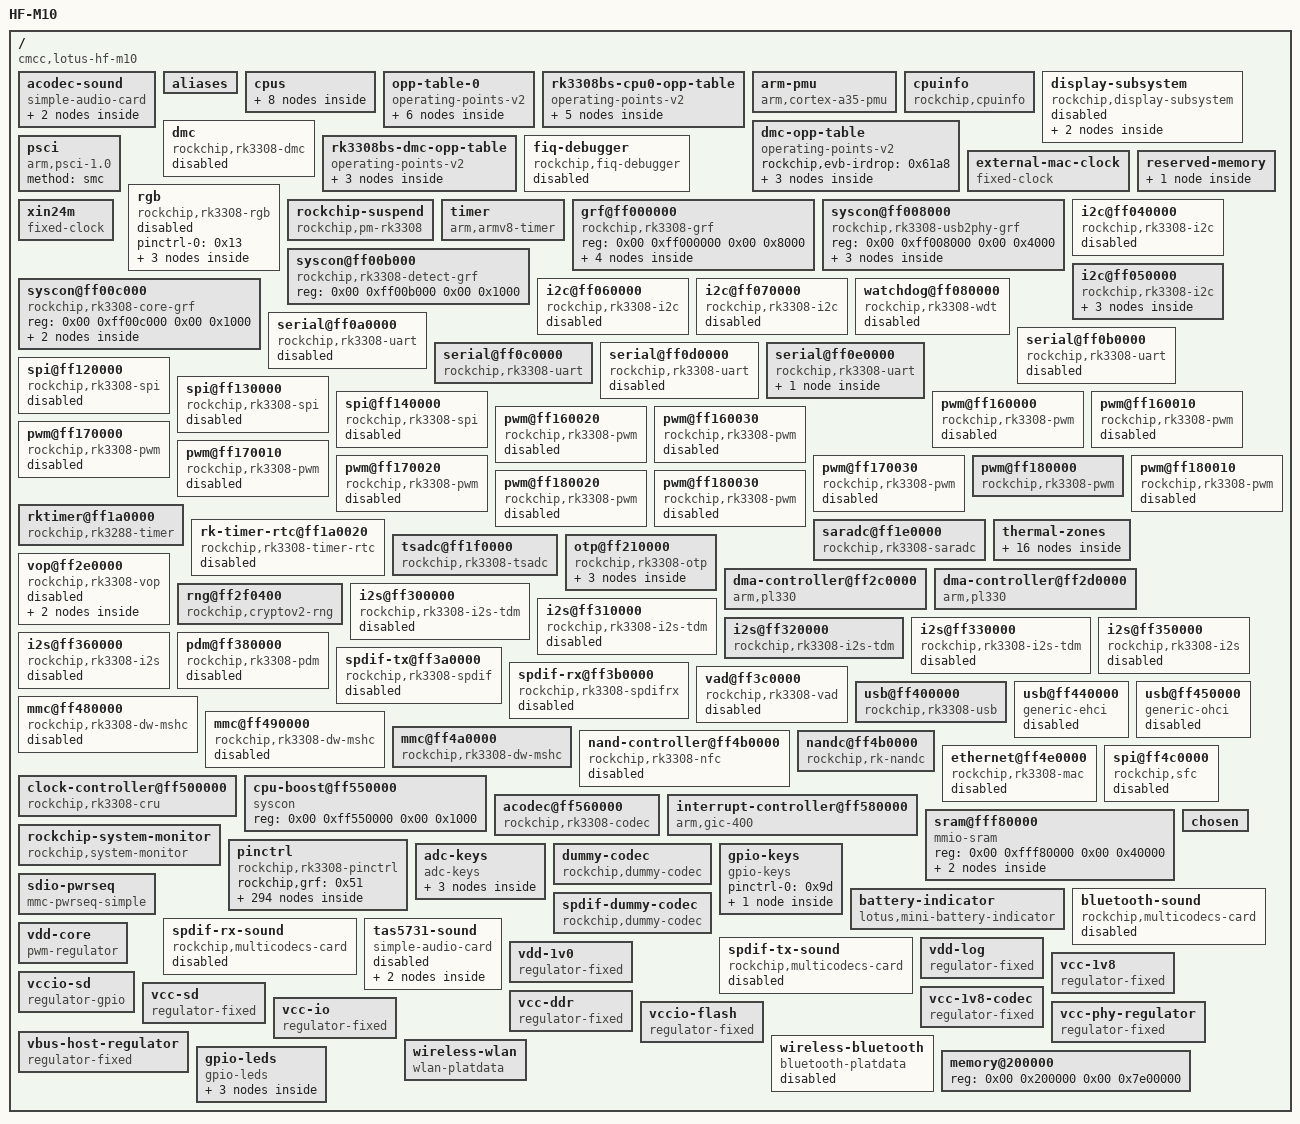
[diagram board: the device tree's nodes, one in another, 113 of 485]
/dts-v1/;

/ {
	compatible = "cmcc,lotus-hf-m10", "lotus,mini-rk3308", "rockchip,rk3308-evb-amic-v11", "rockchip,rk3308";
	interrupt-parent = <0x01>;
	#address-cells = <0x02>;
	#size-cells = <0x02>;
	model = "HF-M10";

	acodec-sound {
		simple-audio-card,mclk-fs = <0x100>;
		simple-audio-card,format = "i2s";
		simple-audio-card,name = "LotusMini";
		compatible = "simple-audio-card";

		simple-audio-card,codec {
			sound-dai = <0xa0>;
		};

		simple-audio-card,cpu {
			sound-dai = <0x9f>;
		};
	};

	aliases {
		ethernet0 = "/ethernet@ff4e0000";
		gpio0 = "/pinctrl/gpio@ff220000";
		gpio1 = "/pinctrl/gpio@ff230000";
		gpio2 = "/pinctrl/gpio@ff240000";
		gpio3 = "/pinctrl/gpio@ff250000";
		gpio4 = "/pinctrl/gpio@ff260000";
		i2c0 = "/i2c@ff040000";
		i2c1 = "/i2c@ff050000";
		i2c2 = "/i2c@ff060000";
		i2c3 = "/i2c@ff070000";
		serial0 = "/serial@ff0a0000";
		serial1 = "/serial@ff0b0000";
		serial2 = "/serial@ff0c0000";
		serial3 = "/serial@ff0d0000";
		serial4 = "/serial@ff0e0000";
		spi0 = "/spi@ff120000";
		spi1 = "/spi@ff130000";
		spi2 = "/spi@ff140000";
	};

	cpus {
		#address-cells = <0x02>;
		#size-cells = <0x00>;

		cpu@0 {
			device_type = "cpu";
			compatible = "arm,cortex-a35";
			reg = <0x00 0x00>;
			enable-method = "psci";
			clocks = <0x02 0x05>;
			#cooling-cells = <0x02>;
			dynamic-power-coefficient = <0x53>;
			operating-points-v2 = <0x03 0x04>;
			cpu-idle-states = <0x05>;
			next-level-cache = <0x06>;
			cpu-supply = <0x07>;
			phandle = <0x09>;

			power-model {
				compatible = "simple-power-model";
				leakage-range = <0x05 0x32>;
				ls = <0x17c6 0x18ca 0xffffffc1>;
				static-coefficient = <0x186a0>;
				ts = <0xfffe55b6 0x18c54 0xfffff9ac 0x1e>;
				thermal-zone = "soc-thermal";
			};
		};

		cpu@1 {
			device_type = "cpu";
			compatible = "arm,cortex-a35";
			reg = <0x00 0x01>;
			enable-method = "psci";
			operating-points-v2 = <0x03 0x04>;
			cpu-idle-states = <0x05>;
			next-level-cache = <0x06>;
			phandle = <0x0a>;
		};

		cpu@2 {
			device_type = "cpu";
			compatible = "arm,cortex-a35";
			reg = <0x00 0x02>;
			enable-method = "psci";
			operating-points-v2 = <0x03 0x04>;
			cpu-idle-states = <0x05>;
			next-level-cache = <0x06>;
			phandle = <0x0b>;
		};

		cpu@3 {
			device_type = "cpu";
			compatible = "arm,cortex-a35";
			reg = <0x00 0x03>;
			enable-method = "psci";
			operating-points-v2 = <0x03 0x04>;
			cpu-idle-states = <0x05>;
			next-level-cache = <0x06>;
			phandle = <0x0c>;
		};

		idle-states {
			entry-method = "psci";

			cpu-sleep {
				compatible = "arm,idle-state";
				local-timer-stop;
				arm,psci-suspend-param = <0x10000>;
				entry-latency-us = <0x78>;
				exit-latency-us = <0xfa>;
				min-residency-us = <0x384>;
				phandle = <0x05>;
			};
		};

		l2-cache {
			compatible = "cache";
			phandle = <0x06>;
		};
	};

	opp-table-0 {
		compatible = "operating-points-v2";
		opp-shared;
		rockchip,temp-hysteresis = <0x1388>;
		rockchip,low-temp = <0x00>;
		rockchip,low-temp-min-volt = <0xf4240>;
		rockchip,max-volt = <0x1437c8>;
		rockchip,low-temp-adjust-volt = <0x00 0x510 0xc350>;
		rockchip,evb-irdrop = <0x61a8>;
		nvmem-cells = <0x08>;
		nvmem-cell-names = "leakage";
		rockchip,pvtm-voltage-sel = <0x00 0xd2f0 0x00 0xd2f1 0xdac0 0x01 0xdac1 0xe484 0x02 0xe485 0xee48 0x03 0xee49 0xf80c 0x04 0xf80d 0x1869f 0x05>;
		rockchip,pvtm-freq = <0x639c0>;
		rockchip,pvtm-volt = <0xfa3e8>;
		rockchip,pvtm-ch = <0x00 0x00>;
		rockchip,pvtm-sample-time = <0x3e8>;
		rockchip,pvtm-number = <0x0a>;
		rockchip,pvtm-error = <0x3e8>;
		rockchip,pvtm-ref-temp = <0x23>;
		rockchip,pvtm-temp-prop = <0xfffffff1 0xffffffdb>;
		rockchip,thermal-zone = "soc-thermal";
		phandle = <0x03>;

		opp-408000000 {
			opp-hz = <0x00 0x18519600>;
			opp-microvolt = <0xe7ef0 0xe7ef0 0x1437c8>;
			clock-latency-ns = <0x9c40>;
			opp-suspend;
		};

		opp-600000000 {
			opp-hz = <0x00 0x23c34600>;
			opp-microvolt = <0xe7ef0 0xe7ef0 0x1437c8>;
			clock-latency-ns = <0x9c40>;
		};

		opp-816000000 {
			opp-hz = <0x00 0x30a32c00>;
			opp-microvolt = <0xfa3e8 0xfa3e8 0x1437c8>;
			opp-microvolt-L0 = <0xfa3e8 0xfa3e8 0x1437c8>;
			opp-microvolt-L1 = <0xfa3e8 0xfa3e8 0x1437c8>;
			opp-microvolt-L2 = <0xfa3e8 0xfa3e8 0x1437c8>;
			opp-microvolt-L3 = <0xf4240 0xf4240 0x1437c8>;
			opp-microvolt-L4 = <0xee098 0xee098 0x1437c8>;
			opp-microvolt-L5 = <0xe7ef0 0xe7ef0 0x1437c8>;
			clock-latency-ns = <0x9c40>;
		};

		opp-1008000000 {
			opp-hz = <0x00 0x3c14dc00>;
			opp-microvolt = <0x112a88 0x112a88 0x1437c8>;
			opp-microvolt-L0 = <0x112a88 0x112a88 0x1437c8>;
			opp-microvolt-L1 = <0x10c8e0 0x10c8e0 0x1437c8>;
			opp-microvolt-L2 = <0x10c8e0 0x10c8e0 0x1437c8>;
			opp-microvolt-L3 = <0x106738 0x106738 0x1437c8>;
			opp-microvolt-L4 = <0x100590 0x100590 0x1437c8>;
			opp-microvolt-L5 = <0xfa3e8 0xfa3e8 0x1437c8>;
			clock-latency-ns = <0x9c40>;
		};

		opp-1200000000 {
			opp-hz = <0x00 0x47868c00>;
			opp-microvolt = <0x1312d0 0x1312d0 0x1437c8>;
			opp-microvolt-L0 = <0x1312d0 0x1312d0 0x1437c8>;
			opp-microvolt-L1 = <0x12b128 0x12b128 0x1437c8>;
			opp-microvolt-L2 = <0x124f80 0x124f80 0x1437c8>;
			opp-microvolt-L3 = <0x11edd8 0x11edd8 0x1437c8>;
			opp-microvolt-L4 = <0x118c30 0x118c30 0x1437c8>;
			opp-microvolt-L5 = <0x112a88 0x112a88 0x1437c8>;
			clock-latency-ns = <0x9c40>;
			status = "okay";
		};

		opp-1296000000 {
			opp-hz = <0x00 0x4d3f6400>;
			opp-microvolt = <0x13d620 0x13d620 0x1437c8>;
			opp-microvolt-L0 = <0x13d620 0x13d620 0x1437c8>;
			opp-microvolt-L1 = <0x137478 0x137478 0x1437c8>;
			opp-microvolt-L2 = <0x1312d0 0x1312d0 0x1437c8>;
			opp-microvolt-L3 = <0x12b128 0x12b128 0x1437c8>;
			opp-microvolt-L4 = <0x124f80 0x124f80 0x1437c8>;
			opp-microvolt-L5 = <0x11edd8 0x11edd8 0x1437c8>;
			clock-latency-ns = <0x9c40>;
			status = "okay";
		};
	};

	rk3308bs-cpu0-opp-table {
		compatible = "operating-points-v2";
		opp-shared;
		rockchip,temp-hysteresis = <0x1388>;
		rockchip,low-temp = <0x00>;
		rockchip,low-temp-min-volt = <0xdbba0>;
		rockchip,max-volt = <0x124f80>;
		rockchip,low-temp-adjust-volt = <0x00 0x4b0 0xc350>;
		rockchip,evb-irdrop = <0x61a8>;
		nvmem-cells = <0x08>;
		nvmem-cell-names = "leakage";
		phandle = <0x04>;

		opp-408000000 {
			opp-hz = <0x00 0x18519600>;
			opp-microvolt = <0xcf850 0xcf850 0x124f80>;
			clock-latency-ns = <0x9c40>;
			opp-suspend;
		};

		opp-600000000 {
			opp-hz = <0x00 0x23c34600>;
			opp-microvolt = <0xdbba0 0xdbba0 0x124f80>;
			clock-latency-ns = <0x9c40>;
		};

		opp-816000000 {
			opp-hz = <0x00 0x30a32c00>;
			opp-microvolt = <0xf4240 0xf4240 0x124f80>;
			clock-latency-ns = <0x9c40>;
		};

		opp-1008000000 {
			opp-hz = <0x00 0x3c14dc00>;
			opp-microvolt = <0x112a88 0x112a88 0x124f80>;
			clock-latency-ns = <0x9c40>;
			status = "okay";
		};

		opp-1104000000 {
			opp-hz = <0x00 0x41cdb400>;
			opp-microvolt = <0x124f80 0x124f80 0x124f80>;
			clock-latency-ns = <0x9c40>;
			status = "okay";
		};
	};

	arm-pmu {
		compatible = "arm,cortex-a35-pmu";
		interrupts = <0x00 0x53 0x04 0x00 0x54 0x04 0x00 0x55 0x04 0x00 0x56 0x04>;
		interrupt-affinity = <0x09 0x0a 0x0b 0x0c>;
	};

	cpuinfo {
		compatible = "rockchip,cpuinfo";
		nvmem-cells = <0x0d>;
		nvmem-cell-names = "id";
	};

	display-subsystem {
		compatible = "rockchip,display-subsystem";
		ports = <0x0e>;
		logo-memory-region = <0x0f>;
		status = "disabled";

		route {

			route-rgb {
				status = "disabled";
				logo,uboot = "logo.bmp";
				logo,kernel = "logo_kernel.bmp";
				logo,mode = "center";
				charge_logo,mode = "center";
				connect = <0x10>;
			};
		};
	};

	dmc {
		compatible = "rockchip,rk3308-dmc";
		clocks = <0x02 0x46>;
		clock-names = "dmc_clk";
		operating-points-v2 = <0x11 0x12>;
		status = "disabled";
	};

	dmc-opp-table {
		compatible = "operating-points-v2";
		rockchip,evb-irdrop = <0x61a8>;
		phandle = <0x11>;

		opp-394000000 {
			opp-hz = <0x00 0x177bf680>;
			opp-microvolt = <0xe7ef0>;
		};

		opp-452000000 {
			opp-hz = <0x00 0x1af0f900>;
			opp-microvolt = <0xee098>;
		};

		opp-590000000 {
			opp-hz = <0x00 0x232aaf80>;
			opp-microvolt = <0xf4240>;
		};
	};

	rk3308bs-dmc-opp-table {
		compatible = "operating-points-v2";
		phandle = <0x12>;

		opp-394000000 {
			opp-hz = <0x00 0x177bf680>;
			opp-microvolt = <0xdbba0>;
		};

		opp-452000000 {
			opp-hz = <0x00 0x1af0f900>;
			opp-microvolt = <0xdbba0>;
		};

		opp-590000000 {
			opp-hz = <0x00 0x232aaf80>;
			opp-microvolt = <0xdbba0>;
		};
	};

	fiq-debugger {
		compatible = "rockchip,fiq-debugger";
		rockchip,serial-id = <0x02>;
		rockchip,wake-irq = <0x00>;
		rockchip,irq-mode-enable = <0x01>;
		rockchip,baudrate = <0x16e360>;
		interrupts = <0x00 0x74 0x04>;
		status = "disabled";
	};

	external-mac-clock {
		compatible = "fixed-clock";
		clock-frequency = <0x2faf080>;
		clock-output-names = "mac_clkin";
		#clock-cells = <0x00>;
		phandle = <0x87>;
	};

	psci {
		compatible = "arm,psci-1.0";
		method = "smc";
	};

	rgb {
		compatible = "rockchip,rk3308-rgb";
		status = "disabled";
		pinctrl-names = "default";
		pinctrl-0 = <0x13>;

		ports {
			#address-cells = <0x01>;
			#size-cells = <0x00>;

			port@0 {
				reg = <0x00>;
				#address-cells = <0x01>;
				#size-cells = <0x00>;

				endpoint@0 {
					reg = <0x00>;
					remote-endpoint = <0x10>;
					phandle = <0x54>;
				};
			};
		};
	};

	reserved-memory {
		#address-cells = <0x02>;
		#size-cells = <0x02>;
		ranges;

		ramoops@110000 {
			compatible = "ramoops";
			reg = <0x00 0x110000 0x00 0xf0000>;
			record-size = <0x30000>;
			console-size = <0xc0000>;
			ftrace-size = <0x00>;
			pmsg-size = <0x00>;
			status = "okay";
		};
	};

	rockchip-suspend {
		compatible = "rockchip,pm-rk3308";
		status = "okay";
		rockchip,sleep-mode-config = <0x08>;
		rockchip,wakeup-config = <0x40000>;
		rockchip,pwm-regulator-config = <0x04>;
	};

	timer {
		compatible = "arm,armv8-timer";
		interrupts = <0x01 0x0d 0xf04 0x01 0x0e 0xf04 0x01 0x0b 0xf04 0x01 0x0a 0xf04>;
	};

	xin24m {
		compatible = "fixed-clock";
		#clock-cells = <0x00>;
		clock-frequency = <0x16e3600>;
		clock-output-names = "xin24m";
		phandle = <0x88>;
	};

	grf@ff000000 {
		compatible = "rockchip,rk3308-grf", "syscon", "simple-mfd";
		reg = <0x00 0xff000000 0x00 0x8000>;
		phandle = <0x51>;

		io-domains {
			compatible = "rockchip,rk3308-io-voltage-domain";
			status = "okay";
			vccio0-supply = <0x14>;
			vccio1-supply = <0x14>;
			vccio2-supply = <0x15>;
			vccio3-supply = <0x16>;
			vccio4-supply = <0x15>;
			vccio5-supply = <0x17>;
		};

		pmu-pvtm {
			compatible = "rockchip,rk3308-pmu-pvtm";
			#address-cells = <0x01>;
			#size-cells = <0x00>;

			pvtm@1 {
				reg = <0x01>;
				clocks = <0x02 0x4a>;
				clock-names = "clk";
			};
		};

		reboot-mode {
			compatible = "syscon-reboot-mode";
			offset = <0x500>;
			mode-bootloader = <0x5242c301>;
			mode-loader = <0x5242c301>;
			mode-normal = <0x5242c300>;
			mode-recovery = <0x5242c303>;
			mode-fastboot = <0x5242c309>;
			mode-panic = <0x5242c307>;
			mode-watchdog = <0x5242c308>;
		};
	};

	syscon@ff008000 {
		compatible = "rockchip,rk3308-usb2phy-grf", "syscon", "simple-mfd";
		reg = <0x00 0xff008000 0x00 0x4000>;
		#address-cells = <0x01>;
		#size-cells = <0x01>;

		usb2phy@100 {
			compatible = "rockchip,rk3308-usb2phy";
			reg = <0x100 0x10>;
			assigned-clocks = <0x02 0x0e>;
			assigned-clock-parents = <0x18>;
			clocks = <0x02 0x48>;
			clock-names = "phyclk";
			clock-output-names = "usb480m_phy";
			#clock-cells = <0x00>;
			status = "okay";
			phandle = <0x18>;

			otg-port {
				interrupts = <0x00 0x43 0x04 0x00 0x44 0x04 0x00 0x45 0x04>;
				interrupt-names = "otg-bvalid", "otg-id", "linestate";
				#phy-cells = <0x00>;
				status = "okay";
				phandle = <0x72>;
			};

			host-port {
				interrupts = <0x00 0x4a 0x04>;
				interrupt-names = "linestate";
				#phy-cells = <0x00>;
				status = "disabled";
				phy-supply = <0x19>;
				phandle = <0x73>;
			};
		};
	};

	syscon@ff00b000 {
		compatible = "rockchip,rk3308-detect-grf", "syscon", "simple-mfd";
		reg = <0x00 0xff00b000 0x00 0x1000>;
		#address-cells = <0x01>;
		#size-cells = <0x01>;
		phandle = <0x8a>;
	};

	syscon@ff00c000 {
		compatible = "rockchip,rk3308-core-grf", "syscon", "simple-mfd";
		reg = <0x00 0xff00c000 0x00 0x1000>;
		#address-cells = <0x01>;
		#size-cells = <0x01>;

		pvtm {
			compatible = "rockchip,rk3308-pvtm";
			#address-cells = <0x01>;
			#size-cells = <0x00>;

			pvtm@0 {
				reg = <0x00>;
				clocks = <0x02 0x10>;
				clock-names = "clk";
			};
		};
	};

	i2c@ff040000 {
		compatible = "rockchip,rk3308-i2c", "rockchip,rk3399-i2c";
		reg = <0x00 0xff040000 0x00 0x1000>;
		clocks = <0x02 0x16 0x02 0xca>;
		clock-names = "i2c", "pclk";
		interrupts = <0x00 0x0b 0x04>;
		pinctrl-names = "default";
		pinctrl-0 = <0x1a>;
		#address-cells = <0x01>;
		#size-cells = <0x00>;
		status = "disabled";
	};

	i2c@ff050000 {
		compatible = "rockchip,rk3308-i2c", "rockchip,rk3399-i2c";
		reg = <0x00 0xff050000 0x00 0x1000>;
		clocks = <0x02 0x17 0x02 0xcb>;
		clock-names = "i2c", "pclk";
		interrupts = <0x00 0x0c 0x04>;
		pinctrl-names = "default";
		pinctrl-0 = <0x1b>;
		#address-cells = <0x01>;
		#size-cells = <0x00>;
		status = "okay";
		clock-frequency = <0x61a80>;

		tas5731@1a {
			#sound-dai-cells = <0x00>;
			compatible = "ti,tas5731";
			reg = <0x1a>;
			clocks = <0x02 0x51>;
			clock-names = "mclk";
			pinctrl-names = "default";
			pinctrl-0 = <0x1c>;
			pdn-gpios = <0x1d 0x05 0x01>;
			reset-gpios = <0x1e 0x01 0x01>;
			status = "disabled";
			phandle = <0xa7>;
		};

		led-controller@3f {
			compatible = "issi,is31fl3236";
			reg = <0x3f>;
			#address-cells = <0x01>;
			#size-cells = <0x00>;
			reset-gpios = <0x1d 0x08 0x00>;
			status = "disabled";

			led@1 {
				label = "is31-test-1";
				reg = <0x01>;
				led-max-microamp = <0x2710>;
			};
		};
	};

	i2c@ff060000 {
		compatible = "rockchip,rk3308-i2c", "rockchip,rk3399-i2c";
		reg = <0x00 0xff060000 0x00 0x1000>;
		clocks = <0x02 0x18 0x02 0xcc>;
		clock-names = "i2c", "pclk";
		interrupts = <0x00 0x0d 0x04>;
		pinctrl-names = "default";
		pinctrl-0 = <0x1f>;
		#address-cells = <0x01>;
		#size-cells = <0x00>;
		status = "disabled";
	};

	i2c@ff070000 {
		compatible = "rockchip,rk3308-i2c", "rockchip,rk3399-i2c";
		reg = <0x00 0xff070000 0x00 0x1000>;
		clocks = <0x02 0x19 0x02 0xcd>;
		clock-names = "i2c", "pclk";
		interrupts = <0x00 0x0e 0x04>;
		pinctrl-names = "default";
		pinctrl-0 = <0x20>;
		#address-cells = <0x01>;
		#size-cells = <0x00>;
		status = "disabled";
	};

	watchdog@ff080000 {
		compatible = "rockchip,rk3308-wdt", "snps,dw-wdt";
		reg = <0x00 0xff080000 0x00 0x100>;
		clocks = <0x02 0xd6>;
		interrupts = <0x00 0x0a 0x04>;
		status = "disabled";
	};

	serial@ff0a0000 {
		compatible = "rockchip,rk3308-uart", "snps,dw-apb-uart";
		reg = <0x00 0xff0a0000 0x00 0x100>;
		interrupts = <0x00 0x12 0x04>;
		clocks = <0x02 0x11 0x02 0xc5>;
		clock-names = "baudclk", "apb_pclk";
		reg-shift = <0x02>;
		reg-io-width = <0x04>;
		dmas = <0x21 0x04 0x21 0x05>;
		dma-names = "tx", "rx";
		pinctrl-names = "default";
		pinctrl-0 = <0x22 0x23 0x24>;
		status = "disabled";
	};

	serial@ff0b0000 {
		compatible = "rockchip,rk3308-uart", "snps,dw-apb-uart";
		reg = <0x00 0xff0b0000 0x00 0x100>;
		interrupts = <0x00 0x13 0x04>;
		clocks = <0x02 0x12 0x02 0xc6>;
		clock-names = "baudclk", "apb_pclk";
		reg-shift = <0x02>;
		reg-io-width = <0x04>;
		dmas = <0x21 0x06 0x21 0x07>;
		dma-names = "tx", "rx";
		pinctrl-names = "default";
		pinctrl-0 = <0x25 0x26 0x27>;
		status = "disabled";
	};

	serial@ff0c0000 {
		compatible = "rockchip,rk3308-uart", "snps,dw-apb-uart";
		reg = <0x00 0xff0c0000 0x00 0x100>;
		interrupts = <0x00 0x14 0x04>;
		clocks = <0x02 0x13 0x02 0xc7>;
		clock-names = "baudclk", "apb_pclk";
		reg-shift = <0x02>;
		reg-io-width = <0x04>;
		dmas = <0x21 0x08 0x21 0x09>;
		dma-names = "tx", "rx";
		status = "okay";
	};

	serial@ff0d0000 {
		compatible = "rockchip,rk3308-uart", "snps,dw-apb-uart";
		reg = <0x00 0xff0d0000 0x00 0x100>;
		interrupts = <0x00 0x15 0x04>;
		clocks = <0x02 0x14 0x02 0xc8>;
		clock-names = "baudclk", "apb_pclk";
		reg-shift = <0x02>;
		reg-io-width = <0x04>;
		dmas = <0x21 0x0a 0x21 0x0b>;
		dma-names = "tx", "rx";
		pinctrl-names = "default";
		pinctrl-0 = <0x28>;
		status = "disabled";
	};

	serial@ff0e0000 {
		compatible = "rockchip,rk3308-uart", "snps,dw-apb-uart";
		reg = <0x00 0xff0e0000 0x00 0x100>;
		interrupts = <0x00 0x16 0x04>;
		clocks = <0x02 0x15 0x02 0xc9>;
		clock-names = "baudclk", "apb_pclk";
		reg-shift = <0x02>;
		reg-io-width = <0x04>;
		pinctrl-names = "default";
		pinctrl-0 = <0x2a 0x2b 0x2c>;
		status = "okay";
		uart-has-rtscts;

		bluetooth {
			compatible = "realtek,rtl8723ds-bt";
			enable-gpios = <0x2d 0x0b 0x00>;
			host-wake-gpios = <0x2d 0x0c 0x00>;
			max-speed = <0x16e360>;
		};
	};

	spi@ff120000 {
		compatible = "rockchip,rk3308-spi", "rockchip,rk3066-spi";
		reg = <0x00 0xff120000 0x00 0x1000>;
		interrupts = <0x00 0x0f 0x04>;
		#address-cells = <0x01>;
		#size-cells = <0x00>;
		clocks = <0x02 0x1b 0x02 0xcf>;
		clock-names = "spiclk", "apb_pclk";
		dmas = <0x21 0x00 0x21 0x01>;
		dma-names = "tx", "rx";
		pinctrl-names = "default", "high_speed";
		pinctrl-0 = <0x2e 0x2f 0x30 0x31>;
		pinctrl-1 = <0x32 0x2f 0x33 0x34>;
		status = "disabled";
	};

	spi@ff130000 {
		compatible = "rockchip,rk3308-spi", "rockchip,rk3066-spi";
		reg = <0x00 0xff130000 0x00 0x1000>;
		interrupts = <0x00 0x10 0x04>;
		#address-cells = <0x01>;
		#size-cells = <0x00>;
		clocks = <0x02 0x1c 0x02 0xd0>;
		clock-names = "spiclk", "apb_pclk";
		dmas = <0x21 0x02 0x21 0x03>;
		dma-names = "tx", "rx";
		pinctrl-names = "default", "high_speed";
		pinctrl-0 = <0x35 0x36 0x37 0x38>;
		pinctrl-1 = <0x39 0x36 0x3a 0x3b>;
		status = "disabled";
	};

	spi@ff140000 {
		compatible = "rockchip,rk3308-spi", "rockchip,rk3066-spi";
		reg = <0x00 0xff140000 0x00 0x1000>;
		interrupts = <0x00 0x11 0x04>;
		#address-cells = <0x01>;
		#size-cells = <0x00>;
		clocks = <0x02 0x1d 0x02 0xd1>;
		clock-names = "spiclk", "apb_pclk";
		dmas = <0x29 0x10 0x29 0x11>;
		dma-names = "tx", "rx";
		pinctrl-names = "default", "high_speed";
		pinctrl-0 = <0x3c 0x3d 0x3e 0x3f>;
		pinctrl-1 = <0x40 0x3d 0x41 0x42>;
		status = "disabled";
	};

	pwm@ff160000 {
		compatible = "rockchip,rk3308-pwm", "rockchip,rk3328-pwm";
		reg = <0x00 0xff160000 0x00 0x10>;
		interrupts = <0x00 0x06 0x04>;
		clocks = <0x02 0x79 0x02 0xe8>;
		clock-names = "pwm", "pclk";
		pinctrl-names = "active";
		pinctrl-0 = <0x43>;
		#pwm-cells = <0x03>;
		status = "disabled";
	};

	pwm@ff160010 {
		compatible = "rockchip,rk3308-pwm", "rockchip,rk3328-pwm";
		reg = <0x00 0xff160010 0x00 0x10>;
		interrupts = <0x00 0x06 0x04>;
		clocks = <0x02 0x79 0x02 0xe8>;
		clock-names = "pwm", "pclk";
		pinctrl-names = "active";
		pinctrl-0 = <0x44>;
		#pwm-cells = <0x03>;
		status = "disabled";
	};

	pwm@ff160020 {
		compatible = "rockchip,rk3308-pwm", "rockchip,rk3328-pwm";
		reg = <0x00 0xff160020 0x00 0x10>;
		interrupts = <0x00 0x06 0x04>;
		clocks = <0x02 0x79 0x02 0xe8>;
		clock-names = "pwm", "pclk";
		pinctrl-names = "active";
		pinctrl-0 = <0x45>;
		#pwm-cells = <0x03>;
		status = "disabled";
	};

	pwm@ff160030 {
		compatible = "rockchip,rk3308-pwm", "rockchip,rk3328-pwm";
		reg = <0x00 0xff160030 0x00 0x10>;
		interrupts = <0x00 0x06 0x04>;
		clocks = <0x02 0x79 0x02 0xe8>;
		clock-names = "pwm", "pclk";
		pinctrl-names = "active";
		pinctrl-0 = <0x46>;
		#pwm-cells = <0x03>;
		status = "disabled";
	};

	pwm@ff170000 {
		compatible = "rockchip,rk3308-pwm", "rockchip,rk3328-pwm";
		reg = <0x00 0xff170000 0x00 0x10>;
		interrupts = <0x00 0x04 0x04>;
		clocks = <0x02 0x78 0x02 0xe7>;
		clock-names = "pwm", "pclk";
		pinctrl-names = "active";
		pinctrl-0 = <0x47>;
		#pwm-cells = <0x03>;
		status = "disabled";
	};

	pwm@ff170010 {
		compatible = "rockchip,rk3308-pwm", "rockchip,rk3328-pwm";
		reg = <0x00 0xff170010 0x00 0x10>;
		interrupts = <0x00 0x04 0x04>;
		clocks = <0x02 0x78 0x02 0xe7>;
		clock-names = "pwm", "pclk";
		pinctrl-names = "active";
		pinctrl-0 = <0x48>;
		#pwm-cells = <0x03>;
		status = "disabled";
	};

	pwm@ff170020 {
		compatible = "rockchip,rk3308-pwm", "rockchip,rk3328-pwm";
		reg = <0x00 0xff170020 0x00 0x10>;
		interrupts = <0x00 0x04 0x04>;
		clocks = <0x02 0x78 0x02 0xe7>;
		clock-names = "pwm", "pclk";
		pinctrl-names = "active";
		pinctrl-0 = <0x49>;
		#pwm-cells = <0x03>;
		status = "disabled";
	};

	pwm@ff170030 {
		compatible = "rockchip,rk3308-pwm", "rockchip,rk3328-pwm";
		reg = <0x00 0xff170030 0x00 0x10>;
		interrupts = <0x00 0x04 0x04>;
		clocks = <0x02 0x78 0x02 0xe7>;
		clock-names = "pwm", "pclk";
		pinctrl-names = "active";
		pinctrl-0 = <0x4a>;
		#pwm-cells = <0x03>;
		status = "disabled";
	};

	pwm@ff180000 {
		compatible = "rockchip,rk3308-pwm", "rockchip,rk3328-pwm";
		reg = <0x00 0xff180000 0x00 0x10>;
		interrupts = <0x00 0x17 0x04>;
		clocks = <0x02 0x1a 0x02 0xce>;
		clock-names = "pwm", "pclk";
		pinctrl-names = "active";
		pinctrl-0 = <0x4b>;
		#pwm-cells = <0x03>;
		status = "okay";
		phandle = <0xa8>;
	};

	pwm@ff180010 {
		compatible = "rockchip,rk3308-pwm", "rockchip,rk3328-pwm";
		reg = <0x00 0xff180010 0x00 0x10>;
		interrupts = <0x00 0x17 0x04>;
		clocks = <0x02 0x1a 0x02 0xce>;
		clock-names = "pwm", "pclk";
		pinctrl-names = "active";
		pinctrl-0 = <0x4c>;
		#pwm-cells = <0x03>;
		status = "disabled";
	};

	pwm@ff180020 {
		compatible = "rockchip,rk3308-pwm", "rockchip,rk3328-pwm";
		reg = <0x00 0xff180020 0x00 0x10>;
		interrupts = <0x00 0x17 0x04>;
		clocks = <0x02 0x1a 0x02 0xce>;
		clock-names = "pwm", "pclk";
		pinctrl-names = "active";
		pinctrl-0 = <0x4d>;
		#pwm-cells = <0x03>;
		status = "disabled";
	};

	pwm@ff180030 {
		compatible = "rockchip,rk3308-pwm", "rockchip,rk3328-pwm";
		reg = <0x00 0xff180030 0x00 0x10>;
		interrupts = <0x00 0x17 0x04>;
		clocks = <0x02 0x1a 0x02 0xce>;
		clock-names = "pwm", "pclk";
		pinctrl-names = "active";
		pinctrl-0 = <0x4e>;
		#pwm-cells = <0x03>;
		status = "disabled";
	};

	rktimer@ff1a0000 {
		compatible = "rockchip,rk3288-timer";
		reg = <0x00 0xff1a0000 0x00 0x20>;
		interrupts = <0x00 0x19 0x04>;
		clocks = <0x02 0xd4 0x02 0x1e>;
		clock-names = "pclk", "timer";
	};

	rk-timer-rtc@ff1a0020 {
		compatible = "rockchip,rk3308-timer-rtc";
		reg = <0x00 0xff1a0020 0x00 0x20>;
		interrupts = <0x00 0x1a 0x04>;
		clocks = <0x02 0xd4 0x02 0x1f>;
		clock-names = "pclk", "timer";
		status = "disabled";
	};

	saradc@ff1e0000 {
		compatible = "rockchip,rk3308-saradc", "rockchip,rk3399-saradc";
		reg = <0x00 0xff1e0000 0x00 0x100>;
		interrupts = <0x00 0x25 0x04>;
		clocks = <0x02 0x25 0x02 0xd2>;
		clock-names = "saradc", "apb_pclk";
		#io-channel-cells = <0x01>;
		resets = <0x02 0x46>;
		reset-names = "saradc-apb";
		status = "okay";
		vref-supply = <0x15>;
		phandle = <0x9c>;
	};

	thermal-zones {

		soc-thermal {
			polling-delay-passive = <0x14>;
			polling-delay = <0x3e8>;
			sustainable-power = <0x168>;
			thermal-sensors = <0x4f 0x00>;

			trips {

				lotus_soc_early: trip-point@0 {
					temperature = <0x11170>;
					hysteresis = <0x7d0>;
					type = "passive";
				};

				trip-point@1 {
					temperature = <0x14c08>;
					hysteresis = <0x7d0>;
					type = "passive";
					phandle = <0x50>;
				};

				soc-crit {
					temperature = <0x1c138>;
					hysteresis = <0x7d0>;
					type = "critical";
				};
			};

			cooling-maps {

				/* Start cooling before the old 85 C target. On this
				 * six-OPP CPU, active states 1..3 cap at 1200..816 MHz.
				 * A lower bound of zero permits full-speed recovery.
				 * The existing 85 C map can request deeper cooling. */
				early-cpu {
					trip = <&lotus_soc_early>;
					cooling-device = <0x09 0 3>;
				};

				map0 {
					trip = <0x50>;
					cooling-device = <0x09 0xffffffff 0xffffffff>;
					contribution = <0x1000>;
				};
			};
		};

		gpu-thermal {
			polling-delay-passive = <0x64>;
			polling-delay = <0x3e8>;
			thermal-sensors = <0x4f 0x01>;

			trips {

				/* Channel 1 is an internal logic sensor, despite
				 * the historical node name. Keep its final protection. */
				lotus_logic_early: logic-passive {
					temperature = <70000>;
					hysteresis = <2000>;
					type = "passive";
				};

				lotus_logic_hot: logic-hot {
					temperature = <85000>;
					hysteresis = <2000>;
					type = "passive";
				};

				gpu_crit {
					temperature = <0x1c138>;
					hysteresis = <0x7d0>;
					type = "critical";
				};
			};

			cooling-maps {
				early-cpu {
					trip = <&lotus_logic_early>;
					cooling-device = <0x09 0 3>;
				};
				hot-cpu {
					trip = <&lotus_logic_hot>;
					cooling-device = <0x09 0xffffffff 0xffffffff>;
				};
			};
		};
	};

	tsadc@ff1f0000 {
		compatible = "rockchip,rk3308-tsadc";
		reg = <0x00 0xff1f0000 0x00 0x100>;
		interrupts = <0x00 0x26 0x04>;
		rockchip,grf = <0x51>;
		clocks = <0x02 0x24 0x02 0xd3>;
		clock-names = "tsadc", "apb_pclk";
		assigned-clocks = <0x02 0x24>;
		assigned-clock-rates = <0xc350>;
		resets = <0x02 0x48>;
		reset-names = "tsadc-apb";
		pinctrl-names = "gpio", "otpout";
		pinctrl-0 = <0x52>;
		pinctrl-1 = <0x53>;
		#thermal-sensor-cells = <0x01>;
		rockchip,hw-tshut-temp = <0x1d4c0>;
		status = "okay";
		rockchip,hw-tshut-mode = <0x00>;
		rockchip,hw-tshut-polarity = <0x01>;
		phandle = <0x4f>;
	};

	otp@ff210000 {
		compatible = "rockchip,rk3308-otp";
		reg = <0x00 0xff210000 0x00 0x4000>;
		#address-cells = <0x01>;
		#size-cells = <0x01>;
		clocks = <0x02 0x27 0x02 0xd5 0x02 0xe5>;
		clock-names = "otp", "apb_pclk", "phy";
		resets = <0x02 0x54>;
		reset-names = "otp_phy";

		id@7 {
			reg = <0x07 0x10>;
			phandle = <0x0d>;
		};

		cpu-leakage@17 {
			reg = <0x17 0x01>;
			phandle = <0x08>;
		};

		logic-leakage@18 {
			reg = <0x18 0x01>;
		};
	};

	dma-controller@ff2c0000 {
		compatible = "arm,pl330", "arm,primecell";
		reg = <0x00 0xff2c0000 0x00 0x4000>;
		interrupts = <0x00 0x00 0x04 0x00 0x01 0x04>;
		arm,pl330-periph-burst;
		clocks = <0x02 0x8a>;
		clock-names = "apb_pclk";
		#dma-cells = <0x01>;
		phandle = <0x21>;
	};

	dma-controller@ff2d0000 {
		compatible = "arm,pl330", "arm,primecell";
		reg = <0x00 0xff2d0000 0x00 0x4000>;
		interrupts = <0x00 0x02 0x04 0x00 0x03 0x04>;
		arm,pl330-periph-burst;
		clocks = <0x02 0x8b>;
		clock-names = "apb_pclk";
		#dma-cells = <0x01>;
		status = "okay";
		phandle = <0x29>;
	};

	vop@ff2e0000 {
		compatible = "rockchip,rk3308-vop";
		reg = <0x00 0xff2e0000 0x00 0x1fc 0x00 0xff2e0a00 0x00 0x400>;
		reg-names = "regs", "gamma_lut";
		interrupts = <0x00 0x2e 0x04>;
		clocks = <0x02 0x88 0x02 0x7d 0x02 0xac>;
		clock-names = "aclk_vop", "dclk_vop", "hclk_vop";
		status = "disabled";

		port {
			#address-cells = <0x01>;
			#size-cells = <0x00>;
			phandle = <0x0e>;

			endpoint@0 {
				reg = <0x00>;
				remote-endpoint = <0x54>;
				phandle = <0x10>;
			};
		};
	};

	rng@ff2f0400 {
		compatible = "rockchip,cryptov2-rng";
		reg = <0x00 0xff2f0400 0x00 0x80>;
		clocks = <0x02 0x29 0x02 0x2a 0x02 0x87 0x02 0xab>;
		clock-names = "clk_crypto", "clk_crypto_apk", "aclk_crypto", "hclk_crypto";
		assigned-clocks = <0x02 0x29 0x02 0x2a 0x02 0x87 0x02 0xab>;
		assigned-clock-rates = <0x8f0d180 0x8f0d180 0xbebc200 0x5f5e100>;
		resets = <0x02 0x24>;
		reset-names = "reset";
		status = "okay";
	};

	i2s@ff300000 {
		compatible = "rockchip,rk3308-i2s-tdm";
		reg = <0x00 0xff300000 0x00 0x1000>;
		interrupts = <0x00 0x30 0x04>;
		clocks = <0x02 0x4c 0x02 0x4e 0x02 0xa4 0x02 0x6e 0x02 0x6f 0x02 0x03 0x02 0x04>;
		clock-names = "mclk_tx", "mclk_rx", "hclk", "mclk_tx_src", "mclk_rx_src", "mclk_root0", "mclk_root1";
		dmas = <0x29 0x00 0x29 0x01>;
		dma-names = "tx", "rx";
		resets = <0x02 0x89 0x02 0x8a>;
		reset-names = "tx-m", "rx-m";
		rockchip,cru = <0x02>;
		rockchip,grf = <0x51>;
		rockchip,mclk-calibrate;
		i2s-lrck-gpio = <0x55 0x07 0x00>;
		pinctrl-names = "default";
		pinctrl-0 = <0x56 0x57 0x58 0x59 0x5a 0x5b 0x5c 0x5d 0x5e 0x5f 0x60 0x61 0x62>;
		status = "disabled";
	};

	i2s@ff310000 {
		compatible = "rockchip,rk3308-i2s-tdm";
		reg = <0x00 0xff310000 0x00 0x1000>;
		interrupts = <0x00 0x31 0x04>;
		clocks = <0x02 0x50 0x02 0x52 0x02 0xa5 0x02 0x70 0x02 0x71 0x02 0x03 0x02 0x04>;
		clock-names = "mclk_tx", "mclk_rx", "hclk", "mclk_tx_src", "mclk_rx_src", "mclk_root0", "mclk_root1";
		dmas = <0x29 0x02 0x29 0x03>;
		dma-names = "tx", "rx";
		resets = <0x02 0x8c 0x02 0x8d>;
		reset-names = "tx-m", "rx-m";
		rockchip,cru = <0x02>;
		rockchip,grf = <0x51>;
		rockchip,mclk-calibrate;
		rockchip,io-multiplex;
		i2s-lrck-gpio = <0x1e 0x05 0x00>;
		status = "disabled";
		#sound-dai-cells = <0x00>;
		pinctrl-names = "default";
		pinctrl-0 = <0x63 0x64 0x65 0x1c>;
		phandle = <0xa6>;
	};

	i2s@ff320000 {
		#sound-dai-cells = <0x00>;
		compatible = "rockchip,rk3308-i2s-tdm";
		reg = <0x00 0xff320000 0x00 0x1000>;
		interrupts = <0x00 0x32 0x04>;
		clocks = <0x02 0x54 0x02 0x56 0x02 0xa6 0x02 0x72 0x02 0x73 0x02 0x03 0x02 0x04>;
		clock-names = "mclk_tx", "mclk_rx", "hclk", "mclk_tx_src", "mclk_rx_src", "mclk_root0", "mclk_root1";
		dmas = <0x29 0x04 0x29 0x05>;
		dma-names = "tx", "rx";
		resets = <0x02 0x8f 0x02 0x90>;
		reset-names = "tx-m", "rx-m";
		rockchip,cru = <0x02>;
		rockchip,grf = <0x51>;
		rockchip,mclk-calibrate;
		status = "okay";
		phandle = <0x9f>;
	};

	i2s@ff330000 {
		compatible = "rockchip,rk3308-i2s-tdm";
		reg = <0x00 0xff330000 0x00 0x1000>;
		interrupts = <0x00 0x33 0x04>;
		clocks = <0x02 0x58 0x02 0x5a 0x02 0xa7 0x02 0x74 0x02 0x75 0x02 0x03 0x02 0x04>;
		clock-names = "mclk_tx", "mclk_rx", "hclk", "mclk_tx_src", "mclk_rx_src", "mclk_root0", "mclk_root1";
		dmas = <0x29 0x07>;
		dma-names = "rx";
		resets = <0x02 0x92 0x02 0x93>;
		reset-names = "tx-m", "rx-m";
		rockchip,cru = <0x02>;
		rockchip,grf = <0x51>;
		rockchip,mclk-calibrate;
		status = "disabled";
	};

	i2s@ff350000 {
		compatible = "rockchip,rk3308-i2s", "rockchip,rk3066-i2s";
		reg = <0x00 0xff350000 0x00 0x1000>;
		interrupts = <0x00 0x34 0x04>;
		clocks = <0x02 0x5c 0x02 0xa8>;
		clock-names = "i2s_clk", "i2s_hclk";
		dmas = <0x29 0x08 0x29 0x09>;
		dma-names = "tx", "rx";
		resets = <0x02 0x95 0x02 0x94>;
		reset-names = "reset-m", "reset-h";
		rockchip,trcm-sync-tx-only;
		pinctrl-names = "default";
		pinctrl-0 = <0x66 0x67 0x68 0x69>;
		status = "disabled";
		phandle = <0xa1>;
	};

	i2s@ff360000 {
		compatible = "rockchip,rk3308-i2s", "rockchip,rk3066-i2s";
		reg = <0x00 0xff360000 0x00 0x1000>;
		interrupts = <0x00 0x35 0x04>;
		clocks = <0x02 0x5e 0x02 0xa9>;
		clock-names = "i2s_clk", "i2s_hclk";
		dmas = <0x29 0x0b>;
		dma-names = "rx";
		resets = <0x02 0x97 0x02 0x96>;
		reset-names = "reset-m", "reset-h";
		status = "disabled";
	};

	pdm@ff380000 {
		compatible = "rockchip,rk3308-pdm", "rockchip,pdm";
		reg = <0x00 0xff380000 0x00 0x1000>;
		clocks = <0x02 0x4b 0x02 0xa1>;
		clock-names = "pdm_clk", "pdm_hclk";
		dmas = <0x29 0x0c>;
		dma-names = "rx";
		resets = <0x02 0x83>;
		reset-names = "pdm-m";
		pinctrl-names = "default";
		pinctrl-0 = <0x6a 0x6b 0x6c 0x6d 0x6e>;
		status = "disabled";
	};

	spdif-tx@ff3a0000 {
		compatible = "rockchip,rk3308-spdif", "rockchip,rk3066-spdif";
		reg = <0x00 0xff3a0000 0x00 0x1000>;
		interrupts = <0x00 0x37 0x04>;
		clocks = <0x02 0x62 0x02 0xa2>;
		clock-names = "mclk", "hclk";
		dmas = <0x29 0x0d>;
		dma-names = "tx";
		pinctrl-names = "default";
		pinctrl-0 = <0x6f>;
		status = "disabled";
		#sound-dai-cells = <0x00>;
		phandle = <0xa4>;
	};

	spdif-rx@ff3b0000 {
		compatible = "rockchip,rk3308-spdifrx";
		reg = <0x00 0xff3b0000 0x00 0x1000>;
		interrupts = <0x00 0x38 0x04>;
		clocks = <0x02 0x65 0x02 0xa3>;
		clock-names = "mclk", "hclk";
		dmas = <0x29 0x0e>;
		dma-names = "rx";
		resets = <0x02 0x87>;
		reset-names = "spdifrx-m";
		pinctrl-names = "default";
		pinctrl-0 = <0x70>;
		status = "disabled";
		#sound-dai-cells = <0x00>;
		phandle = <0xa3>;
	};

	vad@ff3c0000 {
		compatible = "rockchip,rk3308-vad";
		reg = <0x00 0xff3c0000 0x00 0x10000>;
		reg-names = "vad";
		clocks = <0x02 0xaa>;
		clock-names = "hclk";
		interrupts = <0x00 0x39 0x04>;
		rockchip,audio-sram = <0x71>;
		rockchip,audio-src = <0x00>;
		rockchip,det-channel = <0x00>;
		rockchip,mode = <0x00>;
		status = "disabled";
	};

	usb@ff400000 {
		compatible = "rockchip,rk3308-usb", "rockchip,rk3066-usb", "snps,dwc2";
		reg = <0x00 0xff400000 0x00 0x40000>;
		interrupts = <0x00 0x42 0x04>;
		clocks = <0x02 0x9e>;
		clock-names = "otg";
		dr_mode = "peripheral";
		g-np-tx-fifo-size = <0x10>;
		g-rx-fifo-size = <0x118>;
		g-tx-fifo-size = <0x100 0x80 0x80 0x40 0x20 0x10>;
		phys = <0x72>;
		phy-names = "usb2-phy";
		status = "okay";
	};

	usb@ff440000 {
		compatible = "generic-ehci";
		reg = <0x00 0xff440000 0x00 0x10000>;
		interrupts = <0x00 0x47 0x04>;
		clocks = <0x02 0x9f 0x02 0xa0 0x18>;
		clock-names = "usbhost", "arbiter", "utmi";
		phys = <0x73>;
		phy-names = "usb";
		status = "disabled";
	};

	usb@ff450000 {
		compatible = "generic-ohci";
		reg = <0x00 0xff450000 0x00 0x10000>;
		interrupts = <0x00 0x48 0x04>;
		clocks = <0x02 0x9f 0x02 0xa0 0x18>;
		clock-names = "usbhost", "arbiter", "utmi";
		phys = <0x73>;
		phy-names = "usb";
		status = "disabled";
	};

	mmc@ff480000 {
		compatible = "rockchip,rk3308-dw-mshc", "rockchip,rk3288-dw-mshc";
		reg = <0x00 0xff480000 0x00 0x4000>;
		interrupts = <0x00 0x4c 0x04>;
		bus-width = <0x04>;
		clocks = <0x02 0x9a 0x02 0x30 0x02 0x31 0x02 0x32>;
		clock-names = "biu", "ciu", "ciu-drive", "ciu-sample";
		fifo-depth = <0x100>;
		max-frequency = <0x8f0d180>;
		pinctrl-names = "default";
		pinctrl-0 = <0x74 0x75 0x76 0x77>;
		status = "disabled";
		cap-mmc-highspeed;
		cap-sd-highspeed;
		no-sdio;
		no-mmc;
		card-detect-delay = <0x12c>;
		sd-uhs-sdr25;
		sd-uhs-sdr50;
		sd-uhs-sdr104;
		vmmc-supply = <0x78>;
		vqmmc-supply = <0x17>;
	};

	mmc@ff490000 {
		compatible = "rockchip,rk3308-dw-mshc", "rockchip,rk3288-dw-mshc";
		reg = <0x00 0xff490000 0x00 0x4000>;
		interrupts = <0x00 0x4d 0x04>;
		bus-width = <0x08>;
		clocks = <0x02 0x9c 0x02 0x3a 0x02 0x3b 0x02 0x3c>;
		clock-names = "biu", "ciu", "ciu-drive", "ciu-sample";
		fifo-depth = <0x100>;
		max-frequency = <0x8f0d180>;
		status = "disabled";
		cap-mmc-highspeed;
		mmc-hs200-1_8v;
		no-sdio;
		no-sd;
		disable-wp;
		non-removable;
		num-slots = <0x01>;
	};

	mmc@ff4a0000 {
		compatible = "rockchip,rk3308-dw-mshc", "rockchip,rk3288-dw-mshc";
		reg = <0x00 0xff4a0000 0x00 0x4000>;
		interrupts = <0x00 0x4e 0x04>;
		bus-width = <0x04>;
		clocks = <0x02 0x9b 0x02 0x35 0x02 0x36 0x02 0x37>;
		clock-names = "biu", "ciu", "ciu-drive", "ciu-sample";
		fifo-depth = <0x100>;
		/* Stock SDIO bus ceiling: 50 MHz. Validate cold enumeration separately. */
		max-frequency = <50000000>;
		pinctrl-names = "default";
		pinctrl-0 = <0x79 0x7a 0x7b>;
		status = "okay";
		cap-sd-highspeed;
		ignore-pm-notify;
		keep-power-in-suspend;
		non-removable;
		mmc-pwrseq = <0x7c>;
		rockchip,default-drive-phase = <0xb4>;
		supports-sdio;
	};

	nand-controller@ff4b0000 {
		compatible = "rockchip,rk3308-nfc", "rockchip,rv1108-nfc";
		reg = <0x00 0xff4b0000 0x00 0x4000>;
		interrupts = <0x00 0x51 0x04>;
		clocks = <0x02 0x99 0x02 0x2d>;
		clock-names = "ahb", "nfc";
		assigned-clocks = <0x02 0x2d>;
		assigned-clock-rates = <0x8f0d180>;
		pinctrl-0 = <0x7d 0x7e 0x7f 0x80 0x81 0x82 0x83>;
		pinctrl-names = "default";
		status = "disabled";
	};

	nandc@ff4b0000 {
		compatible = "rockchip,rk-nandc";
		reg = <0x00 0xff4b0000 0x00 0x4000>;
		interrupts = <0x00 0x51 0x04>;
		nandc_id = <0x00>;
		clocks = <0x02 0x2d 0x02 0x99>;
		clock-names = "clk_nandc", "hclk_nandc";
		status = "okay";
		pinctrl-names = "default";
		pinctrl-0 = <0x7d 0x7e 0x7f 0x80 0x81 0x82 0x83>;
	};

	ethernet@ff4e0000 {
		compatible = "rockchip,rk3308-mac";
		reg = <0x00 0xff4e0000 0x00 0x10000>;
		interrupts = <0x00 0x40 0x04>;
		interrupt-names = "macirq";
		clocks = <0x02 0x40 0x02 0x42 0x02 0x42 0x02 0x41 0x02 0x40 0x02 0x86 0x02 0xc3 0x02 0x43>;
		clock-names = "stmmaceth", "mac_clk_rx", "mac_clk_tx", "clk_mac_ref", "clk_mac_refout", "aclk_mac", "pclk_mac", "clk_mac_speed";
		phy-mode = "rmii";
		pinctrl-names = "default";
		pinctrl-0 = <0x84 0x85>;
		resets = <0x02 0x7d>;
		reset-names = "stmmaceth";
		rockchip,grf = <0x51>;
		status = "disable";
		phy-supply = <0x86>;
		assigned-clocks = <0x02 0x40>;
		assigned-clock-parents = <0x87>;
		clock_in_out = "input";
		snps,reset-gpio = <0x1d 0x0a 0x01>;
		snps,reset-active-low;
		snps,reset-delays-us = <0x00 0xc350 0xc350>;
	};

	spi@ff4c0000 {
		compatible = "rockchip,sfc";
		reg = <0x00 0xff4c0000 0x00 0x4000>;
		interrupts = <0x00 0x52 0x04>;
		clocks = <0x02 0x3d 0x02 0x9d>;
		clock-names = "clk_sfc", "hclk_sfc";
		assigned-clocks = <0x02 0x3d>;
		assigned-clock-rates = <0x5f5e100>;
		status = "disabled";
	};

	clock-controller@ff500000 {
		compatible = "rockchip,rk3308-cru";
		reg = <0x00 0xff500000 0x00 0x1000>;
		clocks = <0x88>;
		clock-names = "xin24m";
		rockchip,grf = <0x51>;
		rockchip,boost = <0x89>;
		#clock-cells = <0x01>;
		#reset-cells = <0x01>;
		assigned-clocks = <0x02 0x0f>;
		assigned-clock-rates = <0x8000>;
		phandle = <0x02>;
	};

	cpu-boost@ff550000 {
		compatible = "syscon";
		reg = <0x00 0xff550000 0x00 0x1000>;
		phandle = <0x89>;
	};

	acodec@ff560000 {
		#sound-dai-cells = <0x00>;
		compatible = "rockchip,rk3308-codec";
		reg = <0x00 0xff560000 0x00 0x10000>;
		rockchip,grf = <0x51>;
		rockchip,detect-grf = <0x8a>;
		interrupts = <0x00 0x72 0x04 0x00 0x73 0x04>;
		clocks = <0x02 0xc4 0x02 0x55 0x02 0x57>;
		clock-names = "acodec", "mclk_tx", "mclk_rx";
		resets = <0x02 0x99>;
		reset-names = "acodec-reset";
		spk_ctl-gpios = <0x1d 0x05 0x00>;
		status = "okay";
		rockchip,no-deep-low-power;
		rockchip,loopback-grp = <0x00>;
		hp-ctl-gpios = <0x1d 0x01 0x00>;
		spk-ctl-gpios = <0x1d 0x05 0x00>;
		rockchip,no-hp-det;
		rockchip,micbias1;
		rockchip,micbias2;
		rockchip,en-always-grps = <0x02 0x03>;
		rockchip,adc-grps-route = <0x02 0x03 0x01 0x00>;
		phandle = <0xa0>;
	};

	interrupt-controller@ff580000 {
		compatible = "arm,gic-400";
		reg = <0x00 0xff581000 0x00 0x1000 0x00 0xff582000 0x00 0x2000 0x00 0xff584000 0x00 0x2000 0x00 0xff586000 0x00 0x2000>;
		interrupts = <0x01 0x09 0x04>;
		#interrupt-cells = <0x03>;
		interrupt-controller;
		#address-cells = <0x00>;
		phandle = <0x01>;
	};

	sram@fff80000 {
		compatible = "mmio-sram";
		reg = <0x00 0xfff80000 0x00 0x40000>;
		ranges = <0x00 0x00 0xfff80000 0x40000>;
		#address-cells = <0x01>;
		#size-cells = <0x01>;

		ddr-sram@0 {
			reg = <0x00 0x8000>;
		};

		vad-sram@8000 {
			reg = <0x8000 0x38000>;
			phandle = <0x71>;
		};
	};

	rockchip-system-monitor {
		compatible = "rockchip,system-monitor";
		rockchip,thermal-zone = "soc-thermal";
		rockchip,polling-delay = <0xc8>;
	};

	pinctrl {
		compatible = "rockchip,rk3308-pinctrl";
		rockchip,grf = <0x51>;
		#address-cells = <0x02>;
		#size-cells = <0x02>;
		ranges;

		gpio@ff220000 {
			compatible = "rockchip,gpio-bank";
			reg = <0x00 0xff220000 0x00 0x100>;
			interrupts = <0x00 0x28 0x04>;
			clocks = <0x02 0xd7>;
			gpio-controller;
			#gpio-cells = <0x02>;
			interrupt-controller;
			#interrupt-cells = <0x02>;
			phandle = <0x1d>;
		};

		gpio@ff230000 {
			compatible = "rockchip,gpio-bank";
			reg = <0x00 0xff230000 0x00 0x100>;
			interrupts = <0x00 0x29 0x04>;
			clocks = <0x02 0xd8>;
			gpio-controller;
			#gpio-cells = <0x02>;
			interrupt-controller;
			#interrupt-cells = <0x02>;
			phandle = <0x1e>;
		};

		gpio@ff240000 {
			compatible = "rockchip,gpio-bank";
			reg = <0x00 0xff240000 0x00 0x100>;
			interrupts = <0x00 0x2a 0x04>;
			clocks = <0x02 0xd9>;
			gpio-controller;
			#gpio-cells = <0x02>;
			interrupt-controller;
			#interrupt-cells = <0x02>;
			phandle = <0x55>;
		};

		gpio@ff250000 {
			compatible = "rockchip,gpio-bank";
			reg = <0x00 0xff250000 0x00 0x100>;
			interrupts = <0x00 0x2b 0x04>;
			clocks = <0x02 0xda>;
			gpio-controller;
			#gpio-cells = <0x02>;
			interrupt-controller;
			#interrupt-cells = <0x02>;
		};

		gpio@ff260000 {
			compatible = "rockchip,gpio-bank";
			reg = <0x00 0xff260000 0x00 0x100>;
			interrupts = <0x00 0x2c 0x04>;
			clocks = <0x02 0xdb>;
			gpio-controller;
			#gpio-cells = <0x02>;
			interrupt-controller;
			#interrupt-cells = <0x02>;
			phandle = <0x2d>;
		};

		pcfg-pull-up {
			bias-pull-up;
			phandle = <0x9b>;
		};

		pcfg-pull-down {
			bias-pull-down;
			phandle = <0x8e>;
		};

		pcfg-pull-none {
			bias-disable;
			phandle = <0x8b>;
		};

		pcfg-pull-none-2ma {
			bias-disable;
			drive-strength = <0x02>;
		};

		pcfg-pull-up-2ma {
			bias-pull-up;
			drive-strength = <0x02>;
		};

		pcfg-pull-up-4ma {
			bias-pull-up;
			drive-strength = <0x04>;
			phandle = <0x95>;
		};

		pcfg-pull-none-4ma {
			bias-disable;
			drive-strength = <0x04>;
			phandle = <0x96>;
		};

		pcfg-pull-down-4ma {
			bias-pull-down;
			drive-strength = <0x04>;
		};

		pcfg-pull-none-8ma {
			bias-disable;
			drive-strength = <0x08>;
			phandle = <0x8c>;
		};

		pcfg-pull-up-8ma {
			bias-pull-up;
			drive-strength = <0x08>;
			phandle = <0x8d>;
		};

		pcfg-pull-none-12ma {
			bias-disable;
			drive-strength = <0x0c>;
		};

		pcfg-pull-up-12ma {
			bias-pull-up;
			drive-strength = <0x0c>;
			phandle = <0x8f>;
		};

		pcfg-pull-none-smt {
			bias-disable;
			input-schmitt-enable;
			phandle = <0x91>;
		};

		pcfg-output-high {
			output-high;
		};

		pcfg-output-low {
			output-low;
		};

		pcfg-input-high {
			bias-pull-up;
			input-enable;
		};

		pcfg-input {
			input-enable;
		};

		can-m0 {

			canm0-pins {
				rockchip,pins = <0x00 0x0b 0x02 0x8b 0x00 0x0c 0x02 0x8b>;
			};
		};

		can-m1 {

			canm1-pins {
				rockchip,pins = <0x01 0x16 0x05 0x8b 0x01 0x17 0x05 0x8b>;
			};
		};

		can-m2 {

			canm2-pins {
				rockchip,pins = <0x02 0x02 0x04 0x8b 0x02 0x03 0x04 0x8b>;
			};
		};

		emmc {

			emmc-clk {
				rockchip,pins = <0x03 0x09 0x02 0x8c>;
			};

			emmc-cmd {
				rockchip,pins = <0x03 0x08 0x02 0x8d>;
			};

			emmc-pwren {
				rockchip,pins = <0x03 0x0b 0x02 0x8b>;
			};

			emmc-rstn {
				rockchip,pins = <0x03 0x0a 0x02 0x8b>;
			};

			emmc-bus1 {
				rockchip,pins = <0x03 0x00 0x02 0x8d>;
			};

			emmc-bus4 {
				rockchip,pins = <0x03 0x00 0x02 0x8d 0x03 0x01 0x02 0x8d 0x03 0x02 0x02 0x8d 0x03 0x03 0x02 0x8d>;
			};

			emmc-bus8 {
				rockchip,pins = <0x03 0x00 0x02 0x8d 0x03 0x01 0x02 0x8d 0x03 0x02 0x02 0x8d 0x03 0x03 0x02 0x8d 0x03 0x04 0x02 0x8d 0x03 0x05 0x02 0x8d 0x03 0x06 0x02 0x8d 0x03 0x07 0x02 0x8d>;
			};
		};

		ext_micbias {

			ext-micbias-en {
				rockchip,pins = <0x00 0x12 0x00 0x8e>;
			};
		};

		flash {

			flash-csn0 {
				rockchip,pins = <0x03 0x0d 0x01 0x8b>;
				phandle = <0x80>;
			};

			flash-rdy {
				rockchip,pins = <0x03 0x0c 0x01 0x8b>;
				phandle = <0x82>;
			};

			flash-ale {
				rockchip,pins = <0x03 0x0b 0x01 0x8b>;
				phandle = <0x7d>;
			};

			flash-cle {
				rockchip,pins = <0x03 0x09 0x01 0x8b>;
				phandle = <0x7f>;
			};

			flash-wrn {
				rockchip,pins = <0x03 0x08 0x01 0x8b>;
				phandle = <0x83>;
			};

			flash-rdn {
				rockchip,pins = <0x03 0x0a 0x01 0x8b>;
				phandle = <0x81>;
			};

			flash-bus8 {
				rockchip,pins = <0x03 0x00 0x01 0x8f 0x03 0x01 0x01 0x8f 0x03 0x02 0x01 0x8f 0x03 0x03 0x01 0x8f 0x03 0x04 0x01 0x8f 0x03 0x05 0x01 0x8f 0x03 0x06 0x01 0x8f 0x03 0x07 0x01 0x8f>;
				phandle = <0x7e>;
			};
		};

		sfc {

			sfc-bus4 {
				rockchip,pins = <0x03 0x00 0x03 0x8b 0x03 0x01 0x03 0x8b 0x03 0x02 0x03 0x8b 0x03 0x03 0x03 0x8b>;
			};

			sfc-bus2 {
				rockchip,pins = <0x03 0x00 0x03 0x8b 0x03 0x01 0x03 0x8b>;
			};

			sfc-cs0 {
				rockchip,pins = <0x03 0x04 0x03 0x8b>;
			};

			sfc-clk {
				rockchip,pins = <0x03 0x05 0x03 0x8b>;
			};
		};

		gmac {

			rmii-pins {
				rockchip,pins = <0x01 0x11 0x03 0x90 0x01 0x13 0x03 0x90 0x01 0x12 0x03 0x90 0x01 0x14 0x03 0x8b 0x01 0x15 0x03 0x8b 0x01 0x0f 0x03 0x8b 0x01 0x10 0x03 0x8b 0x01 0x0e 0x03 0x8b 0x01 0x0d 0x03 0x8b>;
				phandle = <0x84>;
			};

			mac-refclk-12ma {
				rockchip,pins = <0x01 0x0c 0x03 0x90>;
			};

			mac-refclk {
				rockchip,pins = <0x01 0x0c 0x03 0x8b>;
				phandle = <0x85>;
			};
		};

		gmac-m1 {

			rmiim1-pins {
				rockchip,pins = <0x04 0x0f 0x02 0x90 0x04 0x05 0x02 0x90 0x04 0x04 0x02 0x90 0x04 0x02 0x02 0x8b 0x04 0x03 0x02 0x8b 0x04 0x00 0x02 0x8b 0x04 0x01 0x02 0x8b 0x04 0x0e 0x02 0x8b 0x04 0x0d 0x02 0x8b>;
			};

			macm1-refclk-12ma {
				rockchip,pins = <0x04 0x0c 0x02 0x90>;
			};

			macm1-refclk {
				rockchip,pins = <0x04 0x0c 0x02 0x8b>;
			};
		};

		i2c0 {

			i2c0-xfer {
				rockchip,pins = <0x01 0x18 0x02 0x91 0x01 0x19 0x02 0x91>;
				phandle = <0x1a>;
			};
		};

		i2c1 {

			i2c1-xfer {
				rockchip,pins = <0x00 0x0b 0x01 0x91 0x00 0x0c 0x01 0x91>;
				phandle = <0x1b>;
			};
		};

		i2c2 {

			i2c2-xfer {
				rockchip,pins = <0x02 0x02 0x03 0x91 0x02 0x03 0x03 0x91>;
				phandle = <0x1f>;
			};
		};

		i2c3-m0 {

			i2c3m0-xfer {
				rockchip,pins = <0x00 0x0f 0x02 0x91 0x00 0x10 0x02 0x91>;
				phandle = <0x20>;
			};
		};

		i2c3-m1 {

			i2c3m1-xfer {
				rockchip,pins = <0x03 0x0c 0x02 0x91 0x03 0x0d 0x02 0x91>;
			};
		};

		i2c3-m2 {

			i2c3m2-xfer {
				rockchip,pins = <0x02 0x01 0x03 0x91 0x02 0x00 0x03 0x91>;
			};
		};

		i2s_2ch_0 {

			i2s-2ch-0-mclk {
				rockchip,pins = <0x04 0x0c 0x01 0x91>;
			};

			i2s-2ch-0-sclk {
				rockchip,pins = <0x04 0x0d 0x01 0x91>;
				phandle = <0x66>;
			};

			i2s-2ch-0-lrck {
				rockchip,pins = <0x04 0x0e 0x01 0x92>;
				phandle = <0x67>;
			};

			i2s-2ch-0-sdo {
				rockchip,pins = <0x04 0x0f 0x01 0x93>;
				phandle = <0x69>;
			};

			i2s-2ch-0-sdi {
				rockchip,pins = <0x04 0x10 0x01 0x93>;
				phandle = <0x68>;
			};
		};

		i2s_8ch_0 {

			i2s-8ch-0-mclk {
				rockchip,pins = <0x02 0x04 0x01 0x92>;
				phandle = <0x62>;
			};

			i2s-8ch-0-sclktx {
				rockchip,pins = <0x02 0x05 0x01 0x92>;
				phandle = <0x56>;
			};

			i2s-8ch-0-sclkrx {
				rockchip,pins = <0x02 0x06 0x01 0x92>;
				phandle = <0x57>;
			};

			i2s-8ch-0-lrcktx {
				rockchip,pins = <0x02 0x07 0x01 0x92>;
				phandle = <0x58>;
			};

			i2s-8ch-0-lrckrx {
				rockchip,pins = <0x02 0x08 0x01 0x92>;
				phandle = <0x59>;
			};

			i2s-8ch-0-sdo0 {
				rockchip,pins = <0x02 0x09 0x01 0x93>;
				phandle = <0x5e>;
			};

			i2s-8ch-0-sdo1 {
				rockchip,pins = <0x02 0x0a 0x01 0x93>;
				phandle = <0x5f>;
			};

			i2s-8ch-0-sdo2 {
				rockchip,pins = <0x02 0x0b 0x01 0x93>;
				phandle = <0x60>;
			};

			i2s-8ch-0-sdo3 {
				rockchip,pins = <0x02 0x0c 0x01 0x93>;
				phandle = <0x61>;
			};

			i2s-8ch-0-sdi0 {
				rockchip,pins = <0x02 0x0d 0x01 0x93>;
				phandle = <0x5a>;
			};

			i2s-8ch-0-sdi1 {
				rockchip,pins = <0x02 0x0e 0x01 0x93>;
				phandle = <0x5b>;
			};

			i2s-8ch-0-sdi2 {
				rockchip,pins = <0x02 0x0f 0x01 0x93>;
				phandle = <0x5c>;
			};

			i2s-8ch-0-sdi3 {
				rockchip,pins = <0x02 0x10 0x01 0x93>;
				phandle = <0x5d>;
			};
		};

		i2s_8ch_1_m0 {

			i2s-8ch-1-m0-mclk {
				rockchip,pins = <0x01 0x02 0x02 0x92>;
				phandle = <0x1c>;
			};

			i2s-8ch-1-m0-sclktx {
				rockchip,pins = <0x01 0x03 0x02 0x92>;
				phandle = <0x63>;
			};

			i2s-8ch-1-m0-sclkrx {
				rockchip,pins = <0x01 0x04 0x02 0x92>;
			};

			i2s-8ch-1-m0-lrcktx {
				rockchip,pins = <0x01 0x05 0x02 0x92>;
				phandle = <0x64>;
			};

			i2s-8ch-1-m0-lrckrx {
				rockchip,pins = <0x01 0x06 0x02 0x92>;
			};

			i2s-8ch-1-m0-sdo0 {
				rockchip,pins = <0x01 0x07 0x02 0x93>;
				phandle = <0x65>;
			};

			i2s-8ch-1-m0-sdo1-sdi3 {
				rockchip,pins = <0x01 0x08 0x02 0x93>;
			};

			i2s-8ch-1-m0-sdo2-sdi2 {
				rockchip,pins = <0x01 0x09 0x02 0x93>;
			};

			i2s-8ch-1-m0-sdo3_sdi1 {
				rockchip,pins = <0x01 0x0a 0x02 0x93>;
			};

			i2s-8ch-1-m0-sdi0 {
				rockchip,pins = <0x01 0x0b 0x02 0x93>;
			};
		};

		i2s_8ch_1_m1 {

			i2s-8ch-1-m1-mclk {
				rockchip,pins = <0x01 0x0c 0x02 0x92>;
			};

			i2s-8ch-1-m1-sclktx {
				rockchip,pins = <0x01 0x0d 0x02 0x92>;
			};

			i2s-8ch-1-m1-sclkrx {
				rockchip,pins = <0x01 0x0e 0x02 0x92>;
			};

			i2s-8ch-1-m1-lrcktx {
				rockchip,pins = <0x01 0x0f 0x02 0x92>;
			};

			i2s-8ch-1-m1-lrckrx {
				rockchip,pins = <0x01 0x10 0x02 0x92>;
			};

			i2s-8ch-1-m1-sdo0 {
				rockchip,pins = <0x01 0x11 0x02 0x93>;
			};

			i2s-8ch-1-m1-sdo1-sdi3 {
				rockchip,pins = <0x01 0x12 0x02 0x93>;
			};

			i2s-8ch-1-m1-sdo2-sdi2 {
				rockchip,pins = <0x01 0x13 0x02 0x93>;
			};

			i2s-8ch-1-m1-sdo3_sdi1 {
				rockchip,pins = <0x01 0x14 0x02 0x93>;
			};

			i2s-8ch-1-m1-sdi0 {
				rockchip,pins = <0x01 0x15 0x02 0x93>;
			};
		};

		lcdc {

			lcdc-ctl {
				rockchip,pins = <0x01 0x00 0x01 0x94 0x01 0x01 0x01 0x94 0x01 0x02 0x01 0x94 0x01 0x03 0x01 0x94 0x01 0x04 0x01 0x94 0x01 0x05 0x01 0x94 0x01 0x06 0x01 0x94 0x01 0x07 0x01 0x94 0x01 0x08 0x01 0x94 0x01 0x09 0x01 0x94 0x01 0x0a 0x01 0x94 0x01 0x0b 0x01 0x94 0x01 0x0c 0x01 0x94 0x01 0x0d 0x01 0x94 0x01 0x0e 0x01 0x94 0x01 0x0f 0x01 0x94 0x01 0x10 0x01 0x94 0x01 0x11 0x01 0x94 0x01 0x12 0x01 0x94 0x01 0x13 0x01 0x94 0x01 0x14 0x01 0x94 0x01 0x15 0x01 0x94>;
				phandle = <0x13>;
			};

			lcdc-rgb888-m0 {
				rockchip,pins = <0x01 0x16 0x06 0x94 0x01 0x17 0x06 0x94 0x02 0x09 0x03 0x94 0x02 0x0a 0x03 0x94 0x02 0x0f 0x03 0x94 0x02 0x10 0x03 0x94>;
			};

			lcdc-rgb888-m1 {
				rockchip,pins = <0x03 0x06 0x03 0x94 0x03 0x07 0x03 0x94 0x03 0x08 0x03 0x94 0x03 0x09 0x03 0x94 0x03 0x0a 0x04 0x94 0x03 0x0b 0x04 0x94>;
			};
		};

		owire-m0 {

			owirem0-pins {
				rockchip,pins = <0x00 0x0b 0x03 0x8b>;
			};
		};

		owire-m1 {

			owirem1-pins {
				rockchip,pins = <0x01 0x16 0x07 0x8b>;
			};
		};

		owire-m2 {

			owirem2-pins {
				rockchip,pins = <0x02 0x02 0x05 0x8b>;
			};
		};

		pdm_m0 {

			pdm-m0-clk {
				rockchip,pins = <0x01 0x04 0x03 0x8b>;
			};

			pdm-m0-sdi0 {
				rockchip,pins = <0x01 0x0b 0x03 0x8b>;
			};

			pdm-m0-sdi1 {
				rockchip,pins = <0x01 0x0a 0x03 0x8b>;
			};

			pdm-m0-sdi2 {
				rockchip,pins = <0x01 0x09 0x03 0x8b>;
			};

			pdm-m0-sdi3 {
				rockchip,pins = <0x01 0x08 0x03 0x8b>;
			};
		};

		pdm_m1 {

			pdm-m1-clk {
				rockchip,pins = <0x01 0x0e 0x04 0x8b>;
			};

			pdm-m1-sdi0 {
				rockchip,pins = <0x01 0x15 0x04 0x8b>;
			};

			pdm-m1-sdi1 {
				rockchip,pins = <0x01 0x14 0x04 0x8b>;
			};

			pdm-m1-sdi2 {
				rockchip,pins = <0x01 0x13 0x04 0x8b>;
			};

			pdm-m1-sdi3 {
				rockchip,pins = <0x01 0x12 0x04 0x8b>;
			};
		};

		pdm_m2 {

			pdm-m2-clkm {
				rockchip,pins = <0x02 0x04 0x03 0x8b>;
			};

			pdm-m2-clk {
				rockchip,pins = <0x02 0x06 0x02 0x8b>;
				phandle = <0x6a>;
			};

			pdm-m2-sdi0 {
				rockchip,pins = <0x02 0x0d 0x02 0x8b>;
				phandle = <0x6b>;
			};

			pdm-m2-sdi1 {
				rockchip,pins = <0x02 0x0e 0x02 0x8b>;
				phandle = <0x6c>;
			};

			pdm-m2-sdi2 {
				rockchip,pins = <0x02 0x0f 0x02 0x8b>;
				phandle = <0x6d>;
			};

			pdm-m2-sdi3 {
				rockchip,pins = <0x02 0x10 0x02 0x8b>;
				phandle = <0x6e>;
			};
		};

		pwm0 {

			pwm0-pin {
				rockchip,pins = <0x00 0x0d 0x01 0x8b>;
			};

			pwm0-pin-pull-down {
				rockchip,pins = <0x00 0x0d 0x01 0x8e>;
				phandle = <0x4b>;
			};
		};

		pwm1 {

			pwm1-pin {
				rockchip,pins = <0x00 0x0e 0x01 0x8b>;
				phandle = <0x4c>;
			};

			pwm1-pin-pull-down {
				rockchip,pins = <0x00 0x0e 0x01 0x8e>;
			};
		};

		pwm2 {

			pwm2-pin {
				rockchip,pins = <0x00 0x0f 0x01 0x8b>;
				phandle = <0x4d>;
			};

			pwm2-pin-pull-down {
				rockchip,pins = <0x00 0x0f 0x01 0x8e>;
			};
		};

		pwm3 {

			pwm3-pin {
				rockchip,pins = <0x00 0x10 0x01 0x8b>;
				phandle = <0x4e>;
			};

			pwm3-pin-pull-down {
				rockchip,pins = <0x00 0x10 0x01 0x8e>;
			};
		};

		pwm4 {

			pwm4-pin {
				rockchip,pins = <0x00 0x01 0x02 0x8b>;
				phandle = <0x47>;
			};

			pwm4-pin-pull-down {
				rockchip,pins = <0x00 0x01 0x02 0x8e>;
			};
		};

		pwm5 {

			pwm5-pin {
				rockchip,pins = <0x00 0x11 0x02 0x8b>;
				phandle = <0x48>;
			};

			pwm5-pin-pull-down {
				rockchip,pins = <0x00 0x11 0x02 0x8e>;
			};
		};

		pwm6 {

			pwm6-pin {
				rockchip,pins = <0x00 0x12 0x02 0x8b>;
				phandle = <0x49>;
			};

			pwm6-pin-pull-down {
				rockchip,pins = <0x00 0x12 0x02 0x8e>;
			};
		};

		pwm7 {

			pwm7-pin {
				rockchip,pins = <0x02 0x08 0x02 0x8b>;
				phandle = <0x4a>;
			};

			pwm7-pin-pull-down {
				rockchip,pins = <0x02 0x08 0x02 0x8e>;
			};
		};

		pwm8 {

			pwm8-pin {
				rockchip,pins = <0x02 0x0a 0x02 0x8b>;
				phandle = <0x43>;
			};

			pwm8-pin-pull-down {
				rockchip,pins = <0x02 0x0a 0x02 0x8e>;
			};
		};

		pwm9 {

			pwm9-pin {
				rockchip,pins = <0x02 0x0b 0x02 0x8b>;
				phandle = <0x44>;
			};

			pwm9-pin-pull-down {
				rockchip,pins = <0x02 0x0b 0x02 0x8e>;
			};
		};

		pwm10 {

			pwm10-pin {
				rockchip,pins = <0x02 0x0c 0x02 0x8b>;
				phandle = <0x45>;
			};

			pwm10-pin-pull-down {
				rockchip,pins = <0x02 0x0c 0x02 0x8e>;
			};
		};

		pwm11 {

			pwm11-pin {
				rockchip,pins = <0x02 0x10 0x04 0x8b>;
				phandle = <0x46>;
			};

			pwm11-pin-pull-down {
				rockchip,pins = <0x02 0x10 0x04 0x8e>;
			};
		};

		rtc {

			rtc-32k {
				rockchip,pins = <0x00 0x13 0x01 0x8b>;
				phandle = <0xac>;
			};
		};

		sdmmc {

			sdmmc-clk {
				rockchip,pins = <0x04 0x1d 0x01 0x94>;
				phandle = <0x74>;
			};

			sdmmc-cmd {
				rockchip,pins = <0x04 0x1c 0x01 0x95>;
				phandle = <0x75>;
			};

			sdmmc-det {
				rockchip,pins = <0x00 0x03 0x01 0x95>;
				phandle = <0x76>;
			};

			sdmmc-pwren {
				rockchip,pins = <0x04 0x1e 0x01 0x96>;
			};

			sdmmc-bus1 {
				rockchip,pins = <0x04 0x18 0x01 0x97>;
			};

			sdmmc-bus4 {
				rockchip,pins = <0x04 0x18 0x01 0x97 0x04 0x19 0x01 0x97 0x04 0x1a 0x01 0x97 0x04 0x1b 0x01 0x97>;
				phandle = <0x77>;
			};

			sdmmc-gpio {
				rockchip,pins = <0x04 0x18 0x00 0x95 0x04 0x19 0x00 0x95 0x04 0x1a 0x00 0x95 0x04 0x1b 0x00 0x95 0x04 0x1c 0x00 0x95 0x04 0x1d 0x00 0x95 0x04 0x1e 0x00 0x95>;
			};
		};

		sdio {

			sdio-clk {
				rockchip,pins = <0x04 0x05 0x01 0x98>;
				phandle = <0x7b>;
			};

			sdio-cmd {
				rockchip,pins = <0x04 0x04 0x01 0x99>;
				phandle = <0x7a>;
			};

			sdio-pwren {
				rockchip,pins = <0x00 0x02 0x01 0x98>;
			};

			sdio-wrpt {
				rockchip,pins = <0x00 0x01 0x01 0x98>;
			};

			sdio-intn {
				rockchip,pins = <0x00 0x00 0x01 0x98>;
			};

			sdio-bus1 {
				rockchip,pins = <0x04 0x00 0x01 0x99>;
			};

			sdio-bus4 {
				rockchip,pins = <0x04 0x00 0x01 0x99 0x04 0x01 0x01 0x99 0x04 0x02 0x01 0x99 0x04 0x03 0x01 0x99>;
				phandle = <0x79>;
			};

			sdio-gpio {
				rockchip,pins = <0x04 0x00 0x00 0x95 0x04 0x01 0x00 0x95 0x04 0x02 0x00 0x95 0x04 0x03 0x00 0x95 0x04 0x04 0x00 0x95 0x04 0x05 0x00 0x95>;
			};
		};

		spdif_in {

			spdif-in {
				rockchip,pins = <0x00 0x12 0x01 0x8b>;
				phandle = <0x70>;
			};
		};

		spdif_out {

			spdif-out {
				rockchip,pins = <0x00 0x11 0x01 0x8b>;
				phandle = <0x6f>;
			};
		};

		spi0 {

			spi0-clk {
				rockchip,pins = <0x02 0x02 0x02 0x95>;
				phandle = <0x2e>;
			};

			spi0-csn0 {
				rockchip,pins = <0x02 0x03 0x02 0x95>;
				phandle = <0x2f>;
			};

			spi0-miso {
				rockchip,pins = <0x02 0x00 0x02 0x95>;
				phandle = <0x30>;
			};

			spi0-mosi {
				rockchip,pins = <0x02 0x01 0x02 0x95>;
				phandle = <0x31>;
			};

			spi0-clk-hs {
				rockchip,pins = <0x02 0x02 0x02 0x9a>;
				phandle = <0x32>;
			};

			spi0-miso-hs {
				rockchip,pins = <0x02 0x00 0x02 0x9a>;
				phandle = <0x33>;
			};

			spi0-mosi-hs {
				rockchip,pins = <0x02 0x01 0x02 0x9a>;
				phandle = <0x34>;
			};
		};

		spi1 {

			spi1-clk {
				rockchip,pins = <0x03 0x0b 0x03 0x95>;
				phandle = <0x35>;
			};

			spi1-csn0 {
				rockchip,pins = <0x03 0x0d 0x03 0x95>;
				phandle = <0x36>;
			};

			spi1-miso {
				rockchip,pins = <0x03 0x0a 0x03 0x95>;
				phandle = <0x37>;
			};

			spi1-mosi {
				rockchip,pins = <0x03 0x0c 0x03 0x95>;
				phandle = <0x38>;
			};

			spi1-clk-hs {
				rockchip,pins = <0x03 0x0b 0x03 0x9a>;
				phandle = <0x39>;
			};

			spi1-miso-hs {
				rockchip,pins = <0x03 0x0a 0x03 0x9a>;
				phandle = <0x3a>;
			};

			spi1-mosi-hs {
				rockchip,pins = <0x03 0x0c 0x03 0x9a>;
				phandle = <0x3b>;
			};
		};

		spi1-m1 {

			spi1m1-miso {
				rockchip,pins = <0x02 0x04 0x02 0x95>;
			};

			spi1m1-mosi {
				rockchip,pins = <0x02 0x05 0x02 0x95>;
			};

			spi1m1-clk {
				rockchip,pins = <0x02 0x07 0x02 0x95>;
			};

			spi1m1-csn0 {
				rockchip,pins = <0x02 0x09 0x02 0x95>;
			};

			spi1m1-miso-hs {
				rockchip,pins = <0x02 0x04 0x02 0x9a>;
			};

			spi1m1-mosi-hs {
				rockchip,pins = <0x02 0x05 0x02 0x9a>;
			};

			spi1m1-clk-hs {
				rockchip,pins = <0x02 0x07 0x02 0x9a>;
			};

			spi1m1-csn0-hs {
				rockchip,pins = <0x02 0x09 0x02 0x9a>;
			};
		};

		spi2 {

			spi2-clk {
				rockchip,pins = <0x01 0x18 0x03 0x95>;
				phandle = <0x3c>;
			};

			spi2-csn0 {
				rockchip,pins = <0x01 0x19 0x03 0x95>;
				phandle = <0x3d>;
			};

			spi2-miso {
				rockchip,pins = <0x01 0x16 0x03 0x95>;
				phandle = <0x3e>;
			};

			spi2-mosi {
				rockchip,pins = <0x01 0x17 0x03 0x95>;
				phandle = <0x3f>;
			};

			spi2-clk-hs {
				rockchip,pins = <0x01 0x18 0x03 0x9a>;
				phandle = <0x40>;
			};

			spi2-miso-hs {
				rockchip,pins = <0x01 0x16 0x03 0x9a>;
				phandle = <0x41>;
			};

			spi2-mosi-hs {
				rockchip,pins = <0x01 0x17 0x03 0x9a>;
				phandle = <0x42>;
			};
		};

		tsadc {

			tsadc-otp-pin {
				rockchip,pins = <0x00 0x0a 0x00 0x8b>;
				phandle = <0x52>;
			};

			tsadc-otp-out {
				rockchip,pins = <0x00 0x0a 0x01 0x8b>;
				phandle = <0x53>;
			};
		};

		uart0 {

			uart0-xfer {
				rockchip,pins = <0x02 0x01 0x01 0x9b 0x02 0x00 0x01 0x9b>;
				phandle = <0x22>;
			};

			uart0-cts {
				rockchip,pins = <0x02 0x02 0x01 0x8b>;
				phandle = <0x23>;
			};

			uart0-rts {
				rockchip,pins = <0x02 0x03 0x01 0x8b>;
				phandle = <0x24>;
			};

			uart0-rts-pin {
				rockchip,pins = <0x02 0x03 0x00 0x8b>;
			};
		};

		uart1 {

			uart1-xfer {
				rockchip,pins = <0x01 0x19 0x01 0x9b 0x01 0x18 0x01 0x9b>;
				phandle = <0x25>;
			};

			uart1-cts {
				rockchip,pins = <0x01 0x16 0x01 0x8b>;
				phandle = <0x26>;
			};

			uart1-rts {
				rockchip,pins = <0x01 0x17 0x01 0x8b>;
				phandle = <0x27>;
			};
		};

		uart2-m0 {

			uart2m0-xfer {
				rockchip,pins = <0x01 0x17 0x02 0x9b 0x01 0x16 0x02 0x9b>;
			};
		};

		uart2-m1 {

			uart2m1-xfer {
				rockchip,pins = <0x04 0x1b 0x02 0x9b 0x04 0x1a 0x02 0x9b>;
			};
		};

		uart3 {

			uart3-xfer {
				rockchip,pins = <0x03 0x0d 0x04 0x9b 0x03 0x0c 0x04 0x9b>;
				phandle = <0x28>;
			};
		};

		uart3-m1 {

			uart3m1-xfer {
				rockchip,pins = <0x00 0x12 0x03 0x9b 0x00 0x11 0x03 0x9b>;
			};
		};

		uart4 {

			uart4-xfer {
				rockchip,pins = <0x04 0x09 0x01 0x9b 0x04 0x08 0x01 0x9b>;
				phandle = <0x2a>;
			};

			uart4-cts {
				rockchip,pins = <0x04 0x06 0x01 0x8b>;
				phandle = <0x2b>;
			};

			uart4-rts {
				rockchip,pins = <0x04 0x07 0x01 0x8b>;
				phandle = <0x2c>;
			};

			uart4-rts-pin {
				rockchip,pins = <0x04 0x07 0x00 0x8b>;
				phandle = <0xaa>;
			};
		};

		lotus-battery {
			lotus_battery_inputs: battery-inputs {
				rockchip,pins = <4 24 0 0x93 4 25 0 0x8e>;
			};
		};

		pcfg-pull-none-0-4ma {
			bias-disable;
			drive-strength-s = <0x04>;
			phandle = <0x93>;
		};

		pcfg-pull-none-0-4ma-smt {
			bias-disable;
			drive-strength-s = <0x04>;
			input-schmitt-enable;
			phandle = <0x92>;
		};

		pcfg-pull-up-0-4ma {
			bias-pull-up;
			drive-strength-s = <0x04>;
		};

		pcfg-pull-down-0-4ma {
			bias-pull-down;
			drive-strength-s = <0x04>;
		};

		pcfg-pull-none-0-6ma {
			bias-disable;
			drive-strength-s = <0x06>;
		};

		pcfg-pull-up-0-6ma {
			bias-pull-up;
			drive-strength-s = <0x06>;
		};

		pcfg-pull-down-0-6ma {
			bias-pull-down;
			drive-strength-s = <0x06>;
		};

		pcfg-pull-none-4-6ma {
			bias-disable;
			drive-strength = <0x04>;
			drive-strength-s = <0x06>;
			phandle = <0x94>;
		};

		pcfg-pull-up-4-6ma {
			bias-pull-up;
			drive-strength = <0x04>;
			drive-strength-s = <0x06>;
			phandle = <0x97>;
		};

		pcfg-pull-down-4-6ma {
			bias-pull-down;
			drive-strength = <0x04>;
			drive-strength-s = <0x06>;
		};

		pcfg-pull-none-8-6ma {
			bias-disable;
			drive-strength = <0x08>;
			drive-strength-s = <0x06>;
			phandle = <0x98>;
		};

		pcfg-pull-up-8-6ma {
			bias-pull-up;
			drive-strength = <0x08>;
			drive-strength-s = <0x06>;
			phandle = <0x99>;
		};

		pcfg-pull-down-8-6ma {
			bias-pull-down;
			drive-strength = <0x08>;
			drive-strength-s = <0x06>;
		};

		pcfg-pull-none-8-4ma {
			bias-disable;
			drive-strength = <0x08>;
			drive-strength-s = <0x04>;
		};

		pcfg-pull-up-8-4ma {
			bias-pull-up;
			drive-strength = <0x08>;
			drive-strength-s = <0x04>;
			phandle = <0x9a>;
		};

		pcfg-pull-down-8-4ma {
			bias-pull-down;
			drive-strength = <0x08>;
			drive-strength-s = <0x04>;
		};

		pcfg-pull-none-12-4ma {
			bias-disable;
			drive-strength = <0x0c>;
			drive-strength-s = <0x04>;
		};

		pcfg-pull-up-12-4ma {
			bias-pull-up;
			drive-strength = <0x0c>;
			drive-strength-s = <0x04>;
		};

		pcfg-pull-down-12-4ma {
			bias-pull-down;
			drive-strength = <0x0c>;
			drive-strength-s = <0x04>;
		};

		pcfg-pull-none-12-6ma {
			bias-disable;
			drive-strength = <0x0c>;
			drive-strength-s = <0x06>;
			phandle = <0x90>;
		};

		pcfg-pull-up-12-6ma {
			bias-pull-up;
			drive-strength = <0x0c>;
			drive-strength-s = <0x06>;
		};

		pcfg-pull-down-12-6ma {
			bias-pull-down;
			drive-strength = <0x0c>;
			drive-strength-s = <0x06>;
		};

		buttons {

			pwr-key {
				rockchip,pins = <0x00 0x06 0x00 0x9b>;
			};

			mic-mute {
				rockchip,pins = <0x04 0x1d 0x00 0x8e>;
				phandle = <0x9d>;
			};
		};

		usb {

			usb-drv {
				rockchip,pins = <0x00 0x15 0x00 0x8b>;
				phandle = <0xa9>;
			};
		};

		sdio-pwrseq {

			wifi-enable-h {
				rockchip,pins = <0x00 0x02 0x00 0x8b>;
				phandle = <0x9e>;
			};
		};

		wireless-bluetooth {

			uart4-gpios {
				rockchip,pins = <0x04 0x07 0x00 0x8b>;
			};
		};

		wireless-wlan {

			wifi-wake-host {
				rockchip,pins = <0x00 0x00 0x00 0x9b>;
				phandle = <0xab>;
			};
		};
	};

	chosen {
		bootargs = "console=ttyS2,1500000n8 rdinit=/init loglevel=8 ignore_loglevel panic=3 oops=panic clk_ignore_unused lotus.root=nand";
	};

	adc-keys {
		compatible = "adc-keys";
		io-channels = <0x9c 0x01>;
		io-channel-names = "buttons";
		poll-interval = <0x64>;
		keyup-threshold-microvolt = <0x1b7740>;

		vol-down-key {
			linux,code = <0x72>;
			label = "volume down";
			press-threshold-microvolt = <0x98580>;
		};

		vol-up-key {
			linux,code = <0x73>;
			label = "volume up";
			press-threshold-microvolt = <0x493e0>;
		};

		mic-mute-key {
			linux,code = <0xf8>;
			label = "microphone mute";
			press-threshold-microvolt = <0xdbf88>;
		};
	};

	dummy-codec {
		compatible = "rockchip,dummy-codec";
		#sound-dai-cells = <0x00>;
		phandle = <0xa2>;
	};

	gpio-keys {
		compatible = "gpio-keys";
		pinctrl-names = "default";
		pinctrl-0 = <0x9d>;

		play-pause-key {
			gpios = <0x2d 0x1d 0x00>;
			linux,code = <0xa4>;
			label = "play/power";
			debounce-interval = <0x64>;
		};
	};

	battery-indicator {
		compatible = "lotus,mini-battery-indicator";
		pinctrl-names = "default";
		pinctrl-0 = <&lotus_battery_inputs>;
		indicator-gpios = <0x2d 25 1>;
		charge-gpios = <0x2d 24 1>;
		status = "okay";
	};

	sdio-pwrseq {
		compatible = "mmc-pwrseq-simple";
		pinctrl-names = "default";
		pinctrl-0 = <0x9e>;
		reset-gpios = <0x1d 0x02 0x01>;
		post-power-on-delay-ms = <0xc8>;
		phandle = <0x7c>;
	};

	bluetooth-sound {
		status = "disabled";
		compatible = "rockchip,multicodecs-card";
		rockchip,card-name = "rockchip,rk3308-pcm";
		rockchip,mclk-fs = <0x80>;
		rockchip,cpu = <0xa1>;
		rockchip,codec = <0xa2>;
		rockchip,format = "dsp_b";
		rockchip,bitclock-inversion = <0x00>;
		rockchip,wait-card-locked = <0x00>;
	};

	spdif-dummy-codec {
		compatible = "rockchip,dummy-codec";
		#sound-dai-cells = <0x00>;
		phandle = <0xa5>;
	};

	spdif-rx-sound {
		status = "disabled";
		compatible = "rockchip,multicodecs-card";
		rockchip,card-name = "rockchip,spdif-rx";
		rockchip,mclk-fs = <0x80>;
		rockchip,cpu = <0xa3>;
		rockchip,codec = <0xa2>;
	};

	spdif-tx-sound {
		status = "disabled";
		compatible = "rockchip,multicodecs-card";
		rockchip,card-name = "rockchip,spdif-tx";
		rockchip,mclk-fs = <0x80>;
		rockchip,cpu = <0xa4>;
		rockchip,codec = <0xa5>;
	};

	tas5731-sound {
		status = "disabled";
		compatible = "simple-audio-card";
		simple-audio-card,format = "i2s";
		simple-audio-card,name = "rockchip,tas5731";
		simple-audio-card,mclk-fs = <0x100>;

		simple-audio-card,cpu {
			sound-dai = <0xa6>;
		};

		simple-audio-card,codec {
			sound-dai = <0xa7>;
		};
	};

	vdd-core {
		compatible = "pwm-regulator";
		pwms = <0xa8 0x00 0x1388 0x01>;
		regulator-name = "vdd_core";
		regulator-min-microvolt = <0xc9e78>;
		regulator-max-microvolt = <0x147260>;
		regulator-init-microvolt = <0xf7cd8>;
		regulator-always-on;
		regulator-boot-on;
		regulator-settling-time-up-us = <0xfa>;
		status = "okay";
		phandle = <0x07>;
	};

	vdd-log {
		compatible = "regulator-fixed";
		regulator-name = "vdd_log";
		regulator-always-on;
		regulator-boot-on;
		regulator-min-microvolt = <0x100590>;
		regulator-max-microvolt = <0x100590>;
	};

	vdd-1v0 {
		compatible = "regulator-fixed";
		regulator-name = "vdd_1v0";
		regulator-always-on;
		regulator-boot-on;
		regulator-min-microvolt = <0xf4240>;
		regulator-max-microvolt = <0xf4240>;
	};

	vcc-1v8 {
		compatible = "regulator-fixed";
		regulator-name = "vcc_1v8";
		regulator-always-on;
		regulator-boot-on;
		regulator-min-microvolt = <0x1b7740>;
		regulator-max-microvolt = <0x1b7740>;
		vin-supply = <0x14>;
		phandle = <0x15>;
	};

	vccio-sd {
		compatible = "regulator-gpio";
		regulator-name = "vccio_sd";
		regulator-min-microvolt = <0x1b7740>;
		regulator-max-microvolt = <0x325aa0>;
		gpios = <0x1d 0x0f 0x00>;
		states = <0x1b7740 0x00 0x325aa0 0x01>;
		phandle = <0x17>;
	};

	vcc-sd {
		compatible = "regulator-fixed";
		gpio = <0x2d 0x1e 0x01>;
		regulator-name = "vcc_sd";
		regulator-min-microvolt = <0x325aa0>;
		regulator-max-microvolt = <0x325aa0>;
		phandle = <0x78>;
	};

	vcc-1v8-codec {
		compatible = "regulator-fixed";
		regulator-name = "vcc_1v8_codec";
		regulator-always-on;
		regulator-boot-on;
		regulator-min-microvolt = <0x1b7740>;
		regulator-max-microvolt = <0x1b7740>;
		vin-supply = <0x14>;
	};

	vcc-ddr {
		compatible = "regulator-fixed";
		regulator-name = "vcc_ddr";
		regulator-always-on;
		regulator-boot-on;
		regulator-min-microvolt = <0x16e360>;
		regulator-max-microvolt = <0x16e360>;
	};

	vcc-io {
		compatible = "regulator-fixed";
		regulator-name = "vcc_io";
		regulator-always-on;
		regulator-boot-on;
		regulator-min-microvolt = <0x325aa0>;
		regulator-max-microvolt = <0x325aa0>;
		phandle = <0x14>;
	};

	vccio-flash {
		compatible = "regulator-fixed";
		regulator-name = "vccio_flash";
		regulator-always-on;
		regulator-boot-on;
		regulator-min-microvolt = <0x1b7740>;
		regulator-max-microvolt = <0x1b7740>;
		phandle = <0x16>;
	};

	vcc-phy-regulator {
		compatible = "regulator-fixed";
		regulator-name = "vcc_phy";
		regulator-always-on;
		regulator-boot-on;
		phandle = <0x86>;
	};

	vbus-host-regulator {
		compatible = "regulator-fixed";
		enable-active-high;
		gpio = <0x1d 0x15 0x00>;
		pinctrl-names = "default";
		pinctrl-0 = <0xa9>;
		regulator-name = "vbus_host";
		phandle = <0x19>;
	};

	wireless-bluetooth {
		compatible = "bluetooth-platdata";
		uart_rts_gpios = <0x2d 0x07 0x01>;
		pinctrl-names = "default", "rts_gpio";
		pinctrl-0 = <0x2c>;
		pinctrl-1 = <0xaa>;
		BT,power_gpio = <0x2d 0x0b 0x00>;
		BT,wake_host_irq = <0x2d 0x0c 0x00>;
		status = "disabled";
	};

	wireless-wlan {
		compatible = "wlan-platdata";
		rockchip,grf = <0x51>;
		pinctrl-names = "default";
		pinctrl-0 = <0xab 0xac>;
		wifi_chip_type = "ap6255";
		WIFI,host_wake_irq = <0x1d 0x00 0x01>;
		status = "okay";
	};

	memory@200000 {
		device_type = "memory";
		reg = <0x00 0x200000 0x00 0x7e00000>;
	};

	gpio-leds {
		compatible = "gpio-leds";

		redled {
			gpios = <0x55 0x01 0x01>;
			label = "redled";
			default-state = "off";
		};

		greenled {
			gpios = <0x55 0x00 0x01>;
			label = "greenled";
			default-state = "off";
		};

		blueled {
			gpios = <0x55 0x02 0x01>;
			label = "blueled";
			default-state = "off";
		};
	};
};
